AUTOSAR XML (schema 4-2-2)
package /STELLANTIS/EPT/ASWCs
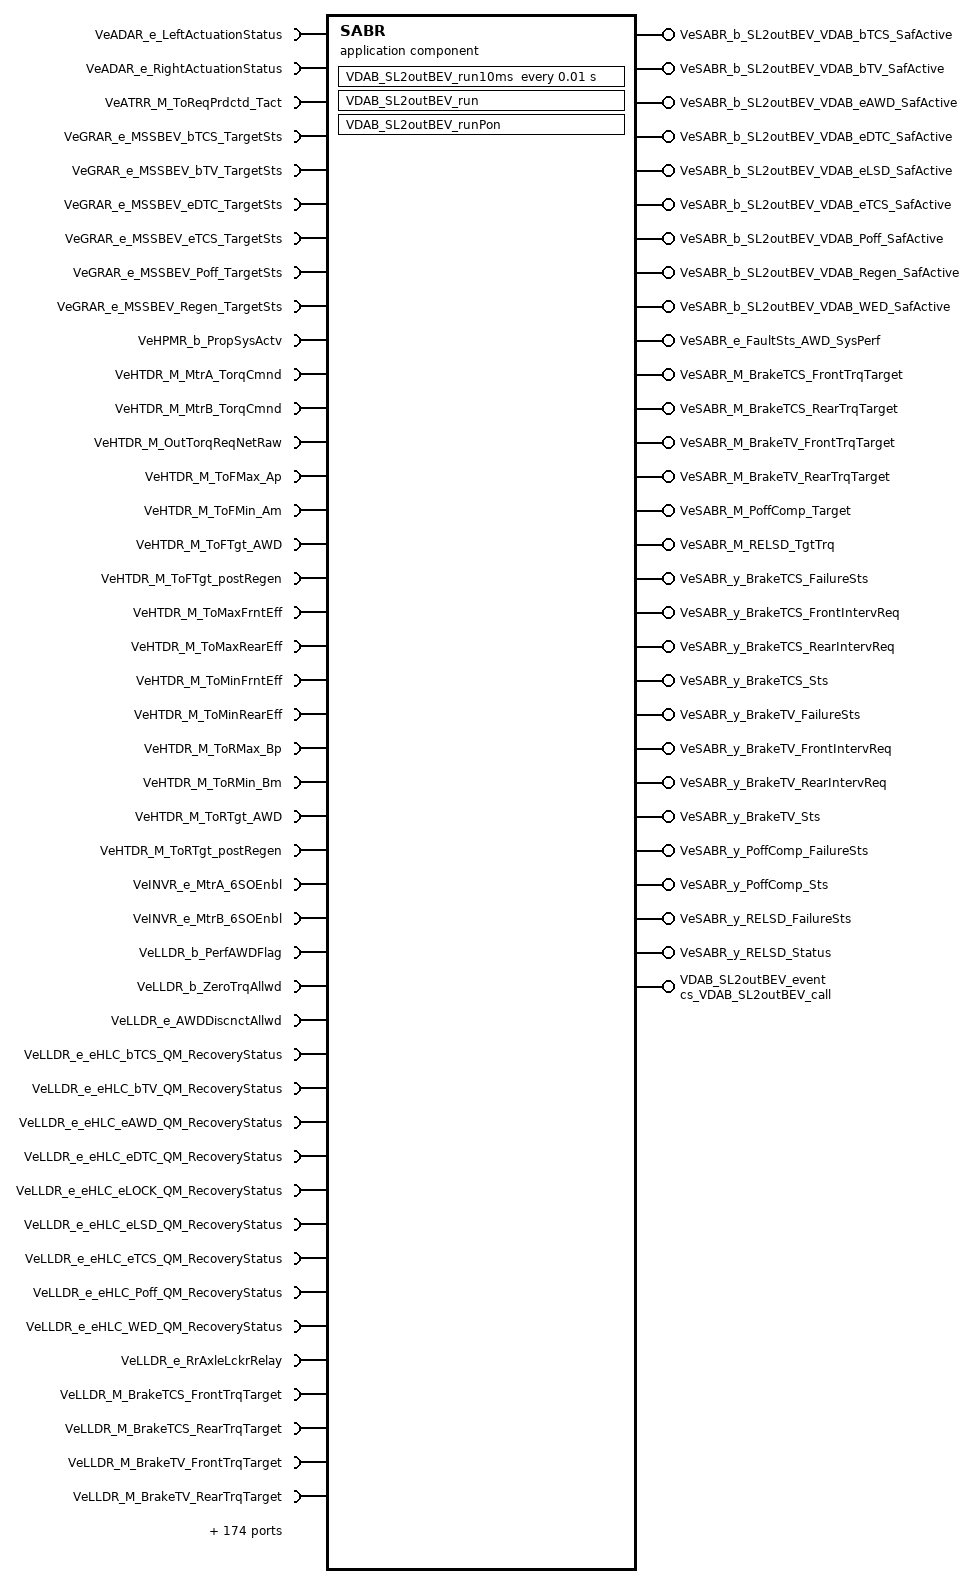
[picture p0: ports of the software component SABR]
  application sw component type SABR
    218 x require port:
      VeADAR_e_LeftActuationStatus: nonqueued-receiver-com-spec{data-element=Value, init-value=CeADAR_e_SS_Indeterminate}, required-interface=VeADAR_e_LeftActuationStatus
      VeADAR_e_RightActuationStatus: nonqueued-receiver-com-spec{data-element=Value, init-value=CeADAR_e_SS_Indeterminate}, required-interface=VeADAR_e_RightActuationStatus
      VeATRR_M_ToReqPrdctd_Tact: nonqueued-receiver-com-spec{data-element=Value, init-value=constant-reference=CONST_VeATRR_M_ToReqPrdctd_Tact_Init}, required-interface=VeATRR_M_ToReqPrdctd_Tact
      VeGRAR_e_MSSBEV_bTCS_TargetSts: nonqueued-receiver-com-spec{data-element=Value, init-value=CeGRAR_e_TargetSts_Disable}, required-interface=VeGRAR_e_MSSBEV_bTCS_TargetSts
      VeGRAR_e_MSSBEV_bTV_TargetSts: nonqueued-receiver-com-spec{data-element=Value, init-value=CeGRAR_e_TargetSts_Disable}, required-interface=VeGRAR_e_MSSBEV_bTV_TargetSts
      VeGRAR_e_MSSBEV_eDTC_TargetSts: nonqueued-receiver-com-spec{data-element=Value, init-value=CeGRAR_e_TargetSts_Disable}, required-interface=VeGRAR_e_MSSBEV_eDTC_TargetSts
      VeGRAR_e_MSSBEV_eTCS_TargetSts: nonqueued-receiver-com-spec{data-element=Value, init-value=CeGRAR_e_TargetSts_Disable}, required-interface=VeGRAR_e_MSSBEV_eTCS_TargetSts
      VeGRAR_e_MSSBEV_Poff_TargetSts: nonqueued-receiver-com-spec{data-element=Value, init-value=CeGRAR_e_TargetSts_Disable}, required-interface=VeGRAR_e_MSSBEV_Poff_TargetSts
      VeGRAR_e_MSSBEV_Regen_TargetSts: nonqueued-receiver-com-spec{data-element=Value, init-value=CeGRAR_e_TargetSts_Disable}, required-interface=VeGRAR_e_MSSBEV_Regen_TargetSts
      VeHPMR_b_PropSysActv: nonqueued-receiver-com-spec{data-element=Value, init-value=constant-reference=CONST_VeHPMR_b_PropSysActv_Init}, required-interface=VeHPMR_b_PropSysActv
      VeHTDR_M_MtrA_TorqCmnd: nonqueued-receiver-com-spec{data-element=Value, init-value=constant-reference=CONST_VeHTDR_M_MtrA_TorqCmnd_Init}, required-interface=VeHTDR_M_MtrA_TorqCmnd
      VeHTDR_M_MtrB_TorqCmnd: nonqueued-receiver-com-spec{data-element=Value, init-value=constant-reference=CONST_VeHTDR_M_MtrB_TorqCmnd_Init}, required-interface=VeHTDR_M_MtrB_TorqCmnd
      VeHTDR_M_OutTorqReqNetRaw: nonqueued-receiver-com-spec{data-element=Value, init-value=constant-reference=CONST_VeHTDR_M_OutTorqReqNetRaw_Init}, required-interface=VeHTDR_M_OutTorqReqNetRaw
      VeHTDR_M_ToFMax_Ap: nonqueued-receiver-com-spec{data-element=Value, init-value=constant-reference=CONST_VeHTDR_M_ToFMax_Ap_Init}, required-interface=VeHTDR_M_ToFMax_Ap
      VeHTDR_M_ToFMin_Am: nonqueued-receiver-com-spec{data-element=Value, init-value=constant-reference=CONST_VeHTDR_M_ToFMin_Am_Init}, required-interface=VeHTDR_M_ToFMin_Am
      VeHTDR_M_ToFTgt_AWD: nonqueued-receiver-com-spec{data-element=Value, init-value=constant-reference=CONST_VeHTDR_M_ToFTgt_AWD_Init}, required-interface=VeHTDR_M_ToFTgt_AWD
      VeHTDR_M_ToFTgt_postRegen: nonqueued-receiver-com-spec{data-element=Value, init-value=constant-reference=CONST_VeHTDR_M_ToFTgt_postRegen_Init}, required-interface=VeHTDR_M_ToFTgt_postRegen
      VeHTDR_M_ToMaxFrntEff: nonqueued-receiver-com-spec{data-element=Value, init-value=constant-reference=CONST_VeHTDR_M_ToMaxFrntEff_Init}, required-interface=VeHTDR_M_ToMaxFrntEff
      VeHTDR_M_ToMaxRearEff: nonqueued-receiver-com-spec{data-element=Value, init-value=constant-reference=CONST_VeHTDR_M_ToMaxRearEff_Init}, required-interface=VeHTDR_M_ToMaxRearEff
      VeHTDR_M_ToMinFrntEff: nonqueued-receiver-com-spec{data-element=Value, init-value=constant-reference=CONST_VeHTDR_M_ToMinFrntEff_Init}, required-interface=VeHTDR_M_ToMinFrntEff
      VeHTDR_M_ToMinRearEff: nonqueued-receiver-com-spec{data-element=Value, init-value=constant-reference=CONST_VeHTDR_M_ToMinRearEff_Init}, required-interface=VeHTDR_M_ToMinRearEff
      VeHTDR_M_ToRMax_Bp: nonqueued-receiver-com-spec{data-element=Value, init-value=constant-reference=CONST_VeHTDR_M_ToRMax_Bp_Init}, required-interface=VeHTDR_M_ToRMax_Bp
      VeHTDR_M_ToRMin_Bm: nonqueued-receiver-com-spec{data-element=Value, init-value=constant-reference=CONST_VeHTDR_M_ToRMin_Bm_Init}, required-interface=VeHTDR_M_ToRMin_Bm
      VeHTDR_M_ToRTgt_AWD: nonqueued-receiver-com-spec{data-element=Value, init-value=constant-reference=CONST_VeHTDR_M_ToRTgt_AWD_Init}, required-interface=VeHTDR_M_ToRTgt_AWD
      VeHTDR_M_ToRTgt_postRegen: nonqueued-receiver-com-spec{data-element=Value, init-value=constant-reference=CONST_VeHTDR_M_ToRTgt_postRegen_Init}, required-interface=VeHTDR_M_ToRTgt_postRegen
      VeINVR_e_MtrA_6SOEnbl: nonqueued-receiver-com-spec{data-element=Value, init-value=CeINVR_e_ThreePS}, required-interface=VeINVR_e_MtrA_6SOEnbl
      VeINVR_e_MtrB_6SOEnbl: nonqueued-receiver-com-spec{data-element=Value, init-value=CeINVR_e_ThreePS}, required-interface=VeINVR_e_MtrB_6SOEnbl
      VeLLDR_b_PerfAWDFlag: nonqueued-receiver-com-spec{data-element=Value, init-value=constant-reference=CONST_VeLLDR_b_eAWD_IntvActv_b_Init}, required-interface=VeLLDR_b_PerfAWDFlag
      VeLLDR_b_ZeroTrqAllwd: nonqueued-receiver-com-spec{data-element=Value, init-value=constant-reference=CONST_VeLLDR_b_eTCS_6SOAllowed_b_Init}, required-interface=VeLLDR_b_ZeroTrqAllwd
      VeLLDR_e_AWDDiscnctAllwd: nonqueued-receiver-com-spec{data-element=Value, init-value=constant-reference=CONST_VeLLDR_e_eTCS_AWDDisconnectAllowed_Init}, required-interface=VeLLDR_e_AWDDiscnctAllwd
      VeLLDR_e_eHLC_bTCS_QM_RecoveryStatus: nonqueued-receiver-com-spec{data-element=Value, init-value=constant-reference=CONST_VeLLDR_y_bTCS_RecoveryStatus_Init}, required-interface=VeLLDR_e_eHLC_bTCS_QM_RecoveryStatus
      VeLLDR_e_eHLC_bTV_QM_RecoveryStatus: nonqueued-receiver-com-spec{data-element=Value, init-value=constant-reference=CONST_VeLLDR_y_bTV_RecoveryStatus_Init}, required-interface=VeLLDR_e_eHLC_bTV_QM_RecoveryStatus
      VeLLDR_e_eHLC_eAWD_QM_RecoveryStatus: nonqueued-receiver-com-spec{data-element=Value, init-value=constant-reference=CONST_VeLLDR_e_eHLC_eAWD_QM_RecoveryStatus}, required-interface=VeLLDR_e_eHLC_eAWD_QM_RecoveryStatus
      VeLLDR_e_eHLC_eDTC_QM_RecoveryStatus: nonqueued-receiver-com-spec{data-element=Value, init-value=constant-reference=CONST_VeLLDR_y_eDTC_RecoveryStatus_Init}, required-interface=VeLLDR_e_eHLC_eDTC_QM_RecoveryStatus
      VeLLDR_e_eHLC_eLOCK_QM_RecoveryStatus: nonqueued-receiver-com-spec{data-element=Value, init-value=constant-reference=CONST_VeLLDR_e_eHLC_eLOCK_QM_RecoveryStatus_Init}, required-interface=VeLLDR_e_eHLC_eLOCK_QM_RecoveryStatus
      VeLLDR_e_eHLC_eLSD_QM_RecoveryStatus: nonqueued-receiver-com-spec{data-element=Value, init-value=constant-reference=CONST_VeLLDR_e_eHLC_eLSD_QM_RecoveryStatus_Init}, required-interface=VeLLDR_e_eHLC_eLSD_QM_RecoveryStatus
      VeLLDR_e_eHLC_eTCS_QM_RecoveryStatus: nonqueued-receiver-com-spec{data-element=Value, init-value=constant-reference=CONST_VeLLDR_y_eTCS_RecoveryStatus_Init}, required-interface=VeLLDR_e_eHLC_eTCS_QM_RecoveryStatus
      VeLLDR_e_eHLC_Poff_QM_RecoveryStatus: nonqueued-receiver-com-spec{data-element=Value, init-value=constant-reference=CONST_VeLLDR_y_Poff_RecoveryStatus_Init}, required-interface=VeLLDR_e_eHLC_Poff_QM_RecoveryStatus
      VeLLDR_e_eHLC_WED_QM_RecoveryStatus: nonqueued-receiver-com-spec{data-element=Value, init-value=constant-reference=CONST_VeLLDR_e_eHLC_WED_QM_RecoveryStatus_Init}, required-interface=VeLLDR_e_eHLC_WED_QM_RecoveryStatus
      VeLLDR_e_RrAxleLckrRelay: nonqueued-receiver-com-spec{data-element=Value, init-value=constant-reference=CONST_VeLLDR_e_eHLC_eLock_RrAxleLckrRelay_Init}, required-interface=VeLLDR_e_RrAxleLckrRelay
      VeLLDR_M_BrakeTCS_FrontTrqTarget: nonqueued-receiver-com-spec{data-element=Value, init-value=constant-reference=CONST_VeLLDR_M_BrakeTCS_FrontTrqTarget_Init}, required-interface=VeLLDR_M_BrakeTCS_FrontTrqTarget
      VeLLDR_M_BrakeTCS_RearTrqTarget: nonqueued-receiver-com-spec{data-element=Value, init-value=constant-reference=CONST_VeLLDR_M_BrakeTCS_RearTrqTarget_Init}, required-interface=VeLLDR_M_BrakeTCS_RearTrqTarget
      VeLLDR_M_BrakeTV_FrontTrqTarget: nonqueued-receiver-com-spec{data-element=Value, init-value=constant-reference=CONST_VeLLDR_M_BrakeTV_FrontTrqTarget_Init}, required-interface=VeLLDR_M_BrakeTV_FrontTrqTarget
      VeLLDR_M_BrakeTV_RearTrqTarget: nonqueued-receiver-com-spec{data-element=Value, init-value=constant-reference=CONST_VeLLDR_M_BrakeTV_RearTrqTarget_Init}, required-interface=VeLLDR_M_BrakeTV_RearTrqTarget
      VeLLDR_M_eHLC_eLSD_RELSD_TgtTrq: nonqueued-receiver-com-spec{data-element=Value, init-value=constant-reference=CONST_VeLLDR_M_eHLC_eLSD_RELSD_TgtTrq_Init}, required-interface=VeLLDR_M_eHLC_eLSD_RELSD_TgtTrq
      VeLLDR_M_FrntAxlAdhMax: nonqueued-receiver-com-spec{data-element=Value, init-value=constant-reference=CONST_VeLLDR_M_eTCS_Adherence_TrqMaxF_Nm_Init}, required-interface=VeLLDR_M_FrntAxlAdhMax
      VeLLDR_M_FrntAxlAdhMin: nonqueued-receiver-com-spec{data-element=Value, init-value=constant-reference=CONST_VeLLDR_M_eTCS_Adherence_TrqMinF_Nm_Init}, required-interface=VeLLDR_M_FrntAxlAdhMin
      VeLLDR_M_FrntAxlEffMax: nonqueued-receiver-com-spec{data-element=Value, init-value=constant-reference=CONST_VeLLDR_M_eTCS_Efficiency_TrqMaxF_Nm_Init}, required-interface=VeLLDR_M_FrntAxlEffMax
      VeLLDR_M_FrntAxlEffMin: nonqueued-receiver-com-spec{data-element=Value, init-value=constant-reference=CONST_VeLLDR_M_eTCS_Efficiency_TrqMinF_Nm_Init}, required-interface=VeLLDR_M_FrntAxlEffMin
      VeLLDR_M_FrntAxlMax_CL: nonqueued-receiver-com-spec{data-element=Value, init-value=constant-reference=CONST_VeLLDR_M_FrntAxlMax_CL_Init}, required-interface=VeLLDR_M_FrntAxlMax_CL
      VeLLDR_M_FrntAxlMax_OL: nonqueued-receiver-com-spec{data-element=Value, init-value=constant-reference=CONST_VeLLDR_M_eTCS_OL_TrqMaxF_Nm_Init}, required-interface=VeLLDR_M_FrntAxlMax_OL
      VeLLDR_M_FrntAxlMin_CL: nonqueued-receiver-com-spec{data-element=Value, init-value=constant-reference=CONST_VeLLDR_M_FrntAxlMin_CL_Init}, required-interface=VeLLDR_M_FrntAxlMin_CL
      VeLLDR_M_FrntAxlMin_OL: nonqueued-receiver-com-spec{data-element=Value, init-value=constant-reference=CONST_VeLLDR_M_eDTC_OL_TrqMinF_Nm_Init}, required-interface=VeLLDR_M_FrntAxlMin_OL
      VeLLDR_M_FrntAxlStrtgcMax_OL: nonqueued-receiver-com-spec{data-element=Value, init-value=constant-reference=CONST_VeLLDR_M_eTCS_OL_Strategic_TrqMaxF_Nm_Init}, required-interface=VeLLDR_M_FrntAxlStrtgcMax_OL
      VeLLDR_M_FrntAxlStrtgcMin_OL: nonqueued-receiver-com-spec{data-element=Value, init-value=constant-reference=CONST_VeLLDR_M_eTCS_OL_Strategic_TrqMinF_Nm_Init}, required-interface=VeLLDR_M_FrntAxlStrtgcMin_OL
      VeLLDR_M_FrntAxlTactFastMax_OL: nonqueued-receiver-com-spec{data-element=Value, init-value=constant-reference=CONST_VeLLDR_M_eTCS_OL_TactFast_TrqMaxF_Nm_Init}, required-interface=VeLLDR_M_FrntAxlTactFastMax_OL
      VeLLDR_M_FrntAxlTactFastMin_OL: nonqueued-receiver-com-spec{data-element=Value, init-value=constant-reference=CONST_VeLLDR_M_eTCS_OL_TactFast_TrqMinF_Nm_Init}, required-interface=VeLLDR_M_FrntAxlTactFastMin_OL
      VeLLDR_M_FrntAxlTactSlowMax_OL: nonqueued-receiver-com-spec{data-element=Value, init-value=constant-reference=CONST_VeLLDR_M_eTCS_OL_TactSlow_TrqMaxF_Nm_Init}, required-interface=VeLLDR_M_FrntAxlTactSlowMax_OL
      VeLLDR_M_FrntAxlTactSlowMin_OL: nonqueued-receiver-com-spec{data-element=Value, init-value=constant-reference=CONST_VeLLDR_M_eTCS_OL_TactSlow_TrqMinF_Nm_Init}, required-interface=VeLLDR_M_FrntAxlTactSlowMin_OL
      VeLLDR_M_PoffComp_Target: nonqueued-receiver-com-spec{data-element=Value, init-value=constant-reference=CONST_VeLLDR_M_PoffComp_Target_Init}, required-interface=VeLLDR_M_PoffComp_Target
      VeLLDR_M_RrAxlAdhMax: nonqueued-receiver-com-spec{data-element=Value, init-value=constant-reference=CONST_VeLLDR_M_eTCS_Adherence_TrqMaxR_Nm_Init}, required-interface=VeLLDR_M_RrAxlAdhMax
      VeLLDR_M_RrAxlAdhMin: nonqueued-receiver-com-spec{data-element=Value, init-value=constant-reference=CONST_VeLLDR_M_eTCS_Adherence_TrqMinR_Nm_Init}, required-interface=VeLLDR_M_RrAxlAdhMin
      VeLLDR_M_RrAxlEffMax: nonqueued-receiver-com-spec{data-element=Value, init-value=constant-reference=CONST_VeLLDR_M_eTCS_Efficiency_TrqMaxR_Nm_Init}, required-interface=VeLLDR_M_RrAxlEffMax
      VeLLDR_M_RrAxlEffMin: nonqueued-receiver-com-spec{data-element=Value, init-value=constant-reference=CONST_VeLLDR_M_eTCS_Efficiency_TrqMinR_Nm_Init}, required-interface=VeLLDR_M_RrAxlEffMin
      VeLLDR_M_RrAxlMax_CL: nonqueued-receiver-com-spec{data-element=Value, init-value=constant-reference=CONST_VeLLDR_M_RrAxlMax_CL_Init}, required-interface=VeLLDR_M_RrAxlMax_CL
      VeLLDR_M_RrAxlMax_OL: nonqueued-receiver-com-spec{data-element=Value, init-value=constant-reference=CONST_VeLLDR_M_eTCS_OL_TrqMaxR_Nm_Init}, required-interface=VeLLDR_M_RrAxlMax_OL
      VeLLDR_M_RrAxlMin_CL: nonqueued-receiver-com-spec{data-element=Value, init-value=constant-reference=CONST_VeLLDR_M_RrAxlMin_CL_Init}, required-interface=VeLLDR_M_RrAxlMin_CL
      VeLLDR_M_RrAxlMin_OL: nonqueued-receiver-com-spec{data-element=Value, init-value=constant-reference=CONST_VeLLDR_M_eDTC_OL_TrqMinR_Nm_Init}, required-interface=VeLLDR_M_RrAxlMin_OL
      VeLLDR_M_RrAxlStrtgcMax_OL: nonqueued-receiver-com-spec{data-element=Value, init-value=constant-reference=CONST_VeLLDR_M_eTCS_OL_Strategic_TrqMaxR_Nm_Init}, required-interface=VeLLDR_M_RrAxlStrtgcMax_OL
      VeLLDR_M_RrAxlStrtgcMin_OL: nonqueued-receiver-com-spec{data-element=Value, init-value=constant-reference=CONST_VeLLDR_M_eTCS_OL_Strategic_TrqMinR_Nm_Init}, required-interface=VeLLDR_M_RrAxlStrtgcMin_OL
      VeLLDR_M_RrAxlTactFastMax_OL: nonqueued-receiver-com-spec{data-element=Value, init-value=constant-reference=CONST_VeLLDR_M_eTCS_OL_TactFast_TrqMaxR_Nm_Init}, required-interface=VeLLDR_M_RrAxlTactFastMax_OL
      VeLLDR_M_RrAxlTactFastMin_OL: nonqueued-receiver-com-spec{data-element=Value, init-value=constant-reference=CONST_VeLLDR_M_eTCS_OL_TactFast_TrqMinR_Nm_Init}, required-interface=VeLLDR_M_RrAxlTactFastMin_OL
      VeLLDR_M_RrAxlTactSlowMax_OL: nonqueued-receiver-com-spec{data-element=Value, init-value=constant-reference=CONST_VeLLDR_M_eTCS_OL_TactSlow_TrqMaxR_Nm_Init}, required-interface=VeLLDR_M_RrAxlTactSlowMax_OL
      VeLLDR_M_RrAxlTactSlowMin_OL: nonqueued-receiver-com-spec{data-element=Value, init-value=constant-reference=CONST_VeLLDR_M_eTCS_OL_TactSlow_TrqMinR_Nm_Init}, required-interface=VeLLDR_M_RrAxlTactSlowMin_OL
      VeLLDR_r_eTCS_TireTolQual_FL: nonqueued-receiver-com-spec{data-element=Value, init-value=constant-reference=CONST_VeLLDR_r_eTCS_TireTolQual_FL_Init}, required-interface=VeLLDR_r_eTCS_TireTolQual_FL
      VeLLDR_r_eTCS_TireTolQual_FR: nonqueued-receiver-com-spec{data-element=Value, init-value=constant-reference=CONST_VeLLDR_r_eTCS_TireTolQual_FR_Init}, required-interface=VeLLDR_r_eTCS_TireTolQual_FR
      VeLLDR_r_eTCS_TireTolQual_RL: nonqueued-receiver-com-spec{data-element=Value, init-value=constant-reference=CONST_VeLLDR_r_eTCS_TireTolQual_RL_Init}, required-interface=VeLLDR_r_eTCS_TireTolQual_RL
      VeLLDR_r_eTCS_TireTolQual_RR: nonqueued-receiver-com-spec{data-element=Value, init-value=constant-reference=CONST_VeLLDR_r_eTCS_TireTolQual_RR_Init}, required-interface=VeLLDR_r_eTCS_TireTolQual_RR
      VeLLDR_r_eTCS_TireTolRatio_FL: nonqueued-receiver-com-spec{data-element=Value, init-value=constant-reference=CONST_VeLLDR_r_eTCS_TireTolRatio_FL_Init}, required-interface=VeLLDR_r_eTCS_TireTolRatio_FL
      VeLLDR_r_eTCS_TireTolRatio_FR: nonqueued-receiver-com-spec{data-element=Value, init-value=constant-reference=CONST_VeLLDR_r_eTCS_TireTolRatio_FR_Init}, required-interface=VeLLDR_r_eTCS_TireTolRatio_FR
      VeLLDR_r_eTCS_TireTolRatio_RL: nonqueued-receiver-com-spec{data-element=Value, init-value=constant-reference=CONST_VeLLDR_r_eTCS_TireTolRatio_RL_Init}, required-interface=VeLLDR_r_eTCS_TireTolRatio_RL
      VeLLDR_r_eTCS_TireTolRatio_RR: nonqueued-receiver-com-spec{data-element=Value, init-value=constant-reference=CONST_VeLLDR_r_eTCS_TireTolRatio_RR_Init}, required-interface=VeLLDR_r_eTCS_TireTolRatio_RR
      VeLLDR_r_RipAWD: nonqueued-receiver-com-spec{data-element=Value, init-value=constant-reference=CONST_VeLLDR_K_eAWD_SplitFactor_Plus_Init}, required-interface=VeLLDR_r_RipAWD
      VeLLDR_r_RipRegen: nonqueued-receiver-com-spec{data-element=Value, init-value=constant-reference=CONST_VeLLDR_K_eAWD_SplitFactor_Minus_Init}, required-interface=VeLLDR_r_RipRegen
      VeLLDR_v_eTCS_VxEst_kmph: nonqueued-receiver-com-spec{data-element=Value, init-value=constant-reference=CONST_VeLLDR_v_eTCS_VxEst_kmph_Init}, required-interface=VeLLDR_v_eTCS_VxEst_kmph
      VeLLDR_y_BrakeTCS_FrontIntervReq: nonqueued-receiver-com-spec{data-element=Value, init-value=constant-reference=CONST_VeLLDR_y_BrakeTCS_FrontIntervReq_Init}, required-interface=VeLLDR_y_BrakeTCS_FrontIntervReq
      VeLLDR_y_BrakeTCS_RearIntervReq: nonqueued-receiver-com-spec{data-element=Value, init-value=constant-reference=CONST_VeLLDR_y_BrakeTCS_RearIntervReq_Init}, required-interface=VeLLDR_y_BrakeTCS_RearIntervReq
      VeLLDR_y_BrakeTV_FrontIntervReq: nonqueued-receiver-com-spec{data-element=Value, init-value=constant-reference=CONST_VeLLDR_y_BrakeTV_FrontIntervReq_Init}, required-interface=VeLLDR_y_BrakeTV_FrontIntervReq
      VeLLDR_y_BrakeTV_RearIntervReq: nonqueued-receiver-com-spec{data-element=Value, init-value=constant-reference=CONST_VeLLDR_y_BrakeTV_RearIntervReq_Init}, required-interface=VeLLDR_y_BrakeTV_RearIntervReq
      VePSMR_b_Lv2AccelPdlPosFlt: nonqueued-receiver-com-spec{data-element=Value, init-value=constant-reference=CONST_VePSMR_b_Lv2AccelPdlPosFlt_Init}, required-interface=VePSMR_b_Lv2AccelPdlPosFlt
      VePSMR_Pct_Lv2AccelPdlPos: nonqueued-receiver-com-spec{data-element=Value, init-value=constant-reference=CONST_VePSMR_Pct_Lv2AccelPdlPos_Init}, required-interface=VePSMR_Pct_Lv2AccelPdlPos
      VeRGNR_M_RegenBrkOutTorqCap_Frnt: nonqueued-receiver-com-spec{data-element=Value, init-value=constant-reference=CONST_VeRGNR_M_RegenBrkOutTorqCap_Frnt_Init}, required-interface=VeRGNR_M_RegenBrkOutTorqCap_Frnt
      VeRGNR_M_RegenBrkOutTorqCap_Rear: nonqueued-receiver-com-spec{data-element=Value, init-value=constant-reference=CONST_VeRGNR_M_RegenBrkOutTorqCap_Rear_Init}, required-interface=VeRGNR_M_RegenBrkOutTorqCap_Rear
      VeRGNR_r_RIPEfficiency: nonqueued-receiver-com-spec{data-element=Value, init-value=constant-reference=CONST_VeRGNR_r_RIPEfficiency_Init}, required-interface=VeRGNR_r_RIPEfficiency
      VeSCMR_a_Lv2LatAcceleration: nonqueued-receiver-com-spec{data-element=Value, init-value=constant-reference=CONST_VeSCMR_a_Lv2LatAcceleration_Init}, required-interface=VeSCMR_a_Lv2LatAcceleration
      VeSCMR_a_Lv2LongAcceleration: nonqueued-receiver-com-spec{data-element=Value, init-value=constant-reference=CONST_VeSCMR_a_Lv2LongAcceleration_Init}, required-interface=VeSCMR_a_Lv2LongAcceleration
      VeSCMR_b_Lv2ABSActive: nonqueued-receiver-com-spec{data-element=Value, init-value=constant-reference=CONST_VeSCMR_b_Lv2ABSActive_Init}, required-interface=VeSCMR_b_Lv2ABSActive
      VeSCMR_b_Lv2ABSActive_FA: nonqueued-receiver-com-spec{data-element=Value, init-value=constant-reference=CONST_VeSCMR_b_Lv2ABSActive_FA_Init}, required-interface=VeSCMR_b_Lv2ABSActive_FA
      VeSCMR_b_Lv2ABSFailSts: nonqueued-receiver-com-spec{data-element=Value, init-value=constant-reference=CONST_VeSCMR_b_Lv2ABSFailSts_Init}, required-interface=VeSCMR_b_Lv2ABSFailSts
      VeSCMR_b_Lv2ABSFailSts_FA: nonqueued-receiver-com-spec{data-element=Value, init-value=constant-reference=CONST_VeSCMR_b_Lv2ABSFailSts_FA_Init}, required-interface=VeSCMR_b_Lv2ABSFailSts_FA
      VeSCMR_b_Lv2ACC_SystemSts_FA: nonqueued-receiver-com-spec{data-element=Value, init-value=constant-reference=CONST_VeSCMR_b_Lv2ACC_SystemSts_FA_Init}, required-interface=VeSCMR_b_Lv2ACC_SystemSts_FA
      VeSCMR_b_Lv2Brk_Stat_FA: nonqueued-receiver-com-spec{data-element=Value, init-value=constant-reference=CONST_VeSCMR_b_Lv2Brk_Stat_FA_Init}, required-interface=VeSCMR_b_Lv2Brk_Stat_FA
      VeSCMR_b_Lv2BrkBoostPressure_FA: nonqueued-receiver-com-spec{data-element=Value, init-value=constant-reference=CONST_VeSCMR_b_Lv2BrkBoostPressure_FA_Init}, required-interface=VeSCMR_b_Lv2BrkBoostPressure_FA
      VeSCMR_b_Lv2BrkPdl_Flt: nonqueued-receiver-com-spec{data-element=Value, init-value=constant-reference=CONST_VeSCMR_b_Lv2BrkPdl_Flt_Init}, required-interface=VeSCMR_b_Lv2BrkPdl_Flt
      VeSCMR_b_Lv2BrkPdl_Flt_FA: nonqueued-receiver-com-spec{data-element=Value, init-value=constant-reference=CONST_VeSCMR_b_Lv2BrkPdl_Flt_FA_Init}, required-interface=VeSCMR_b_Lv2BrkPdl_Flt_FA
      VeSCMR_b_Lv2BrkPdlStat_FA: nonqueued-receiver-com-spec{data-element=Value, init-value=constant-reference=CONST_VeSCMR_b_Lv2BrkPdlStat_FA_Init}, required-interface=VeSCMR_b_Lv2BrkPdlStat_FA
      VeSCMR_b_Lv2BrkTravelSts_FA: nonqueued-receiver-com-spec{data-element=Value, init-value=constant-reference=CONST_VeSCMR_b_Lv2BrkTravelSts_FA_Init}, required-interface=VeSCMR_b_Lv2BrkTravelSts_FA
      VeSCMR_b_Lv2BrkTrq_FA: nonqueued-receiver-com-spec{data-element=Value, init-value=constant-reference=CONST_VeSCMR_b_Lv2BrkTrq_FA_Init}, required-interface=VeSCMR_b_Lv2BrkTrq_FA
      VeSCMR_b_Lv2BrkTrqDriver_FA: nonqueued-receiver-com-spec{data-element=Value, init-value=constant-reference=CONST_VeSCMR_b_Lv2BrkTrqDriver_FA_Init}, required-interface=VeSCMR_b_Lv2BrkTrqDriver_FA
      VeSCMR_b_Lv2EPB_HoldSts_FA: nonqueued-receiver-com-spec{data-element=Value, init-value=constant-reference=CONST_VeSCMR_b_Lv2EPB_HoldSts_FA_Init}, required-interface=VeSCMR_b_Lv2EPB_HoldSts_FA
      VeSCMR_b_Lv2ESC_Active: nonqueued-receiver-com-spec{data-element=Value, init-value=constant-reference=CONST_VeSCMR_b_Lv2ESC_Active_Init}, required-interface=VeSCMR_b_Lv2ESC_Active
      VeSCMR_b_Lv2ESC_Active_FA: nonqueued-receiver-com-spec{data-element=Value, init-value=constant-reference=CONST_VeSCMR_b_Lv2ESC_Active_FA_Init}, required-interface=VeSCMR_b_Lv2ESC_Active_FA
      VeSCMR_b_Lv2ESC_FailSts: nonqueued-receiver-com-spec{data-element=Value, init-value=constant-reference=CONST_VeSCMR_b_Lv2ESC_FailSts_Init}, required-interface=VeSCMR_b_Lv2ESC_FailSts
      VeSCMR_b_Lv2ESC_FailSts_FA: nonqueued-receiver-com-spec{data-element=Value, init-value=constant-reference=CONST_VeSCMR_b_Lv2ESC_FailSts_FA_Init}, required-interface=VeSCMR_b_Lv2ESC_FailSts_FA
      VeSCMR_b_Lv2Function2Sts: nonqueued-receiver-com-spec{data-element=Value, init-value=constant-reference=CONST_VeSCMR_b_Lv2Function2Sts_Init}, required-interface=VeSCMR_b_Lv2Function2Sts
      VeSCMR_b_Lv2Function2Sts_FA: nonqueued-receiver-com-spec{data-element=Value, init-value=constant-reference=CONST_VeSCMR_b_Lv2Function2Sts_FA_Init}, required-interface=VeSCMR_b_Lv2Function2Sts_FA
      VeSCMR_b_Lv2GearShiftType_FA: nonqueued-receiver-com-spec{data-element=Value, init-value=constant-reference=CONST_VeSCMR_b_Lv2GearShiftType_FA_Init}, required-interface=VeSCMR_b_Lv2GearShiftType_FA
      VeSCMR_b_Lv2KeySts_FA: nonqueued-receiver-com-spec{data-element=Value, init-value=constant-reference=CONST_VeSCMR_b_Lv2KeySts_FA_Init}, required-interface=VeSCMR_b_Lv2KeySts_FA
      VeSCMR_b_Lv2LatAcceleration_FA: nonqueued-receiver-com-spec{data-element=Value, init-value=constant-reference=CONST_VeSCMR_b_Lv2LatAcceleration_FA_Init}, required-interface=VeSCMR_b_Lv2LatAcceleration_FA
      VeSCMR_b_Lv2LatAccelerationFailSts: nonqueued-receiver-com-spec{data-element=Value, init-value=constant-reference=CONST_VeSCMR_b_Lv2LatAccelerationFailSts_Init}, required-interface=VeSCMR_b_Lv2LatAccelerationFailSts
      VeSCMR_b_Lv2LatAccelerationFailSts_FA: nonqueued-receiver-com-spec{data-element=Value, init-value=constant-reference=CONST_VeSCMR_b_Lv2LatAccelerationFailSts_FA_Init}, required-interface=VeSCMR_b_Lv2LatAccelerationFailSts_FA
      VeSCMR_b_Lv2LongAcceleration_FA: nonqueued-receiver-com-spec{data-element=Value, init-value=constant-reference=CONST_VeSCMR_b_Lv2LongAcceleration_FA_Init}, required-interface=VeSCMR_b_Lv2LongAcceleration_FA
      VeSCMR_b_Lv2LongAccelerationFailSts: nonqueued-receiver-com-spec{data-element=Value, init-value=constant-reference=CONST_VeSCMR_b_Lv2LongAccelerationFailSts_Init}, required-interface=VeSCMR_b_Lv2LongAccelerationFailSts
      VeSCMR_b_Lv2LongAccelerationFailSts_FA: nonqueued-receiver-com-spec{data-element=Value, init-value=constant-reference=CONST_VeSCMR_b_Lv2LongAccelerationFailSts_FA_Init}, required-interface=VeSCMR_b_Lv2LongAccelerationFailSts_FA
      VeSCMR_b_Lv2LwsAngle_FA: nonqueued-receiver-com-spec{data-element=Value, init-value=constant-reference=CONST_VeSCMR_b_Lv2LwsAngle_FA_Init}, required-interface=VeSCMR_b_Lv2LwsAngle_FA
      VeSCMR_b_Lv2MRGB_Current_Gr_FA: nonqueued-receiver-com-spec{data-element=Value, init-value=constant-reference=CONST_VeSCMR_b_Lv2MRGB_Current_Gr_FA_Init}, required-interface=VeSCMR_b_Lv2MRGB_Current_Gr_FA
      VeSCMR_b_Lv2MRGB_Target_Gr_FA: nonqueued-receiver-com-spec{data-element=Value, init-value=constant-reference=CONST_VeSCMR_b_Lv2MRGB_Target_Gr_FA_Init}, required-interface=VeSCMR_b_Lv2MRGB_Target_Gr_FA
      VeSCMR_b_Lv2MtrA_MaxTrq_FA: nonqueued-receiver-com-spec{data-element=Value, init-value=constant-reference=CONST_VeSCMR_b_Lv2MtrA_MaxTrq_FA_Init}, required-interface=VeSCMR_b_Lv2MtrA_MaxTrq_FA
      VeSCMR_b_Lv2MtrA_MinTrq_FA: nonqueued-receiver-com-spec{data-element=Value, init-value=constant-reference=CONST_VeSCMR_b_Lv2MtrA_MinTrq_FA_Init}, required-interface=VeSCMR_b_Lv2MtrA_MinTrq_FA
      VeSCMR_b_Lv2MtrA_Spd_Vld: nonqueued-receiver-com-spec{data-element=Value, init-value=constant-reference=CONST_VeSCMR_b_Lv2MtrA_Spd_Vld_Init}, required-interface=VeSCMR_b_Lv2MtrA_Spd_Vld
      VeSCMR_b_Lv2MtrA_TrqAchieved_Vld: nonqueued-receiver-com-spec{data-element=Value, init-value=constant-reference=CONST_VeSCMR_b_Lv2MtrA_TrqAchieved_Vld_Init}, required-interface=VeSCMR_b_Lv2MtrA_TrqAchieved_Vld
      VeSCMR_b_Lv2MtrA_TrqAchieved_NoAEMD_FA: nonqueued-receiver-com-spec{data-element=Value, init-value=constant-reference=CONST_VeSCMR_b_Lv2MtrA_TrqAchieved_NoAEMD_FA_Init}, required-interface=VeSCMR_b_Lv2MtrA_TrqAchieved_NoAEMD_FA
      VeSCMR_b_Lv2MtrB_MaxTrq_FA: nonqueued-receiver-com-spec{data-element=Value, init-value=constant-reference=CONST_VeSCMR_b_Lv2MtrB_MaxTrq_FA_Init}, required-interface=VeSCMR_b_Lv2MtrB_MaxTrq_FA
      VeSCMR_b_Lv2MtrB_MinTrq_FA: nonqueued-receiver-com-spec{data-element=Value, init-value=constant-reference=CONST_VeSCMR_b_Lv2MtrB_MinTrq_FA_Init}, required-interface=VeSCMR_b_Lv2MtrB_MinTrq_FA
      VeSCMR_b_Lv2MtrB_Spd_Vld: nonqueued-receiver-com-spec{data-element=Value, init-value=constant-reference=CONST_VeSCMR_b_Lv2MtrB_Spd_Vld_Init}, required-interface=VeSCMR_b_Lv2MtrB_Spd_Vld
      VeSCMR_b_Lv2MtrB_TrqAchieved_Vld: nonqueued-receiver-com-spec{data-element=Value, init-value=constant-reference=CONST_VeSCMR_b_Lv2MtrB_TrqAchieved_Vld_Init}, required-interface=VeSCMR_b_Lv2MtrB_TrqAchieved_Vld
      VeSCMR_b_Lv2MtrB_TrqAchieved_NoAEMD_FA: nonqueued-receiver-com-spec{data-element=Value, init-value=constant-reference=CONST_VeSCMR_b_Lv2MtrB_TrqAchieved_NoAEMD_FA_Init}, required-interface=VeSCMR_b_Lv2MtrB_TrqAchieved_NoAEMD_FA
      VeSCMR_b_Lv2OperationalModeSts_FA: nonqueued-receiver-com-spec{data-element=Value, init-value=constant-reference=CONST_VeSCMR_b_Lv2OperationalModeSts_FA_Init}, required-interface=VeSCMR_b_Lv2OperationalModeSts_FA
      VeSCMR_b_Lv2RollsModeAct: nonqueued-receiver-com-spec{data-element=Value, init-value=constant-reference=CONST_VeSCMR_b_Lv2RollsModeAct_Init}, required-interface=VeSCMR_b_Lv2RollsModeAct
      VeSCMR_b_Lv2RollsModeAct_FA: nonqueued-receiver-com-spec{data-element=Value, init-value=constant-reference=CONST_VeSCMR_b_Lv2RollsModeAct_FA_Init}, required-interface=VeSCMR_b_Lv2RollsModeAct_FA
      VeSCMR_b_Lv2RrLkTrq_FA: nonqueued-receiver-com-spec{data-element=Value, init-value=constant-reference=CONST_VeSR1B_y_RrLkTrq_SigSts_Init}, required-interface=VeSCMR_b_Lv2RrLkTrq_FA
      VeSCMR_b_Lv2RrSysStat_FA: nonqueued-receiver-com-spec{data-element=Value, init-value=constant-reference=CONST_VeSCMR_b_Lv2RrSysStat_FA_Init}, required-interface=VeSCMR_b_Lv2RrSysStat_FA
      VeSCMR_b_Lv2RrTemp_Avl_FA: nonqueued-receiver-com-spec{data-element=Value, init-value=constant-reference=CONST_VeSCMR_b_Lv2RrTemp_Avl_FA_Init}, required-interface=VeSCMR_b_Lv2RrTemp_Avl_FA
      VeSCMR_b_Lv2TransTrqRatio_FA: nonqueued-receiver-com-spec{data-element=Value, init-value=constant-reference=CONST_VeSCMR_b_Lv2TransTrqRatio_FA_Init}, required-interface=VeSCMR_b_Lv2TransTrqRatio_FA
      VeSCMR_b_Lv2WhlDirFL_Stat_FA: nonqueued-receiver-com-spec{data-element=Value, init-value=constant-reference=CONST_VeSCMR_b_Lv2WhlDirFL_Stat_FA_Init}, required-interface=VeSCMR_b_Lv2WhlDirFL_Stat_FA
      VeSCMR_b_Lv2WhlDirFR_Stat_FA: nonqueued-receiver-com-spec{data-element=Value, init-value=constant-reference=CONST_VeSCMR_b_Lv2WhlDirFR_Stat_FA_Init}, required-interface=VeSCMR_b_Lv2WhlDirFR_Stat_FA
      VeSCMR_b_Lv2WhlDirRL_Stat_FA: nonqueued-receiver-com-spec{data-element=Value, init-value=constant-reference=CONST_VeSCMR_b_Lv2WhlDirRL_Stat_FA_Init}, required-interface=VeSCMR_b_Lv2WhlDirRL_Stat_FA
      VeSCMR_b_Lv2WhlDirRR_Stat_FA: nonqueued-receiver-com-spec{data-element=Value, init-value=constant-reference=CONST_VeSCMR_b_Lv2WhlDirRR_Stat_FA_Init}, required-interface=VeSCMR_b_Lv2WhlDirRR_Stat_FA
      VeSCMR_b_Lv2WhlFL_Spd_FA: nonqueued-receiver-com-spec{data-element=Value, init-value=constant-reference=CONST_VeSCMR_b_Lv2WhlFL_Spd_FA_Init}, required-interface=VeSCMR_b_Lv2WhlFL_Spd_FA
      VeSCMR_b_Lv2WhlFR_Spd_FA: nonqueued-receiver-com-spec{data-element=Value, init-value=constant-reference=CONST_VeSCMR_b_Lv2WhlFR_Spd_FA_Init}, required-interface=VeSCMR_b_Lv2WhlFR_Spd_FA
      VeSCMR_b_Lv2WhlRL_Spd_FA: nonqueued-receiver-com-spec{data-element=Value, init-value=constant-reference=CONST_VeSCMR_b_Lv2WhlRL_Spd_FA_Init}, required-interface=VeSCMR_b_Lv2WhlRL_Spd_FA
      VeSCMR_b_Lv2WhlRR_Spd_FA: nonqueued-receiver-com-spec{data-element=Value, init-value=constant-reference=CONST_VeSCMR_b_Lv2WhlRR_Spd_FA_Init}, required-interface=VeSCMR_b_Lv2WhlRR_Spd_FA
      VeSCMR_b_Lv2WhlSensFailFL: nonqueued-receiver-com-spec{data-element=Value, init-value=constant-reference=CONST_VeSCMR_b_Lv2WhlSensFailFL_Init}, required-interface=VeSCMR_b_Lv2WhlSensFailFL
      VeSCMR_b_Lv2WhlSensFailFL_FA: nonqueued-receiver-com-spec{data-element=Value, init-value=constant-reference=CONST_VeSCMR_b_Lv2WhlSensFailFL_FA_Init}, required-interface=VeSCMR_b_Lv2WhlSensFailFL_FA
      VeSCMR_b_Lv2WhlSensFailFR: nonqueued-receiver-com-spec{data-element=Value, init-value=constant-reference=CONST_VeSCMR_b_Lv2WhlSensFailFR_Init}, required-interface=VeSCMR_b_Lv2WhlSensFailFR
      VeSCMR_b_Lv2WhlSensFailFR_FA: nonqueued-receiver-com-spec{data-element=Value, init-value=constant-reference=CONST_VeSCMR_b_Lv2WhlSensFailFR_FA_Init}, required-interface=VeSCMR_b_Lv2WhlSensFailFR_FA
      VeSCMR_b_Lv2WhlSensFailRL: nonqueued-receiver-com-spec{data-element=Value, init-value=constant-reference=CONST_VeSCMR_b_Lv2WhlSensFailRL_Init}, required-interface=VeSCMR_b_Lv2WhlSensFailRL
      VeSCMR_b_Lv2WhlSensFailRL_FA: nonqueued-receiver-com-spec{data-element=Value, init-value=constant-reference=CONST_VeSCMR_b_Lv2WhlSensFailRL_FA_Init}, required-interface=VeSCMR_b_Lv2WhlSensFailRL_FA
      VeSCMR_b_Lv2WhlSensFailRR: nonqueued-receiver-com-spec{data-element=Value, init-value=constant-reference=CONST_VeSCMR_b_Lv2WhlSensFailRR_Init}, required-interface=VeSCMR_b_Lv2WhlSensFailRR
      VeSCMR_b_Lv2WhlSensFailRR_FA: nonqueued-receiver-com-spec{data-element=Value, init-value=constant-reference=CONST_VeSCMR_b_Lv2WhlSensFailRR_FA_Init}, required-interface=VeSCMR_b_Lv2WhlSensFailRR_FA
      VeSCMR_b_Lv2YawRate_FA: nonqueued-receiver-com-spec{data-element=Value, init-value=constant-reference=CONST_VeSCMR_b_Lv2YawRate_FA_Init}, required-interface=VeSCMR_b_Lv2YawRate_FA
      VeSCMR_b_Lv2YawRateFailSts: nonqueued-receiver-com-spec{data-element=Value, init-value=constant-reference=CONST_VeSCMR_b_Lv2YawRateFailSts_Init}, required-interface=VeSCMR_b_Lv2YawRateFailSts
      VeSCMR_b_Lv2YawRateFailSts_FA: nonqueued-receiver-com-spec{data-element=Value, init-value=constant-reference=CONST_VeSCMR_b_Lv2YawRateFailSts_FA_Init}, required-interface=VeSCMR_b_Lv2YawRateFailSts_FA
      VeSCMR_dphi_Lv2YawRate: nonqueued-receiver-com-spec{data-element=Value, init-value=constant-reference=CONST_VeSCMR_dphi_Lv2YawRate_Init}, required-interface=VeSCMR_dphi_Lv2YawRate
      VeSCMR_e_Lv2ACC_SystemSts: nonqueued-receiver-com-spec{data-element=Value, init-value=CeSTMR_e_Off_M182}, required-interface=VeSCMR_e_Lv2ACC_SystemSts
      VeSCMR_e_Lv2Brk_Stat: nonqueued-receiver-com-spec{data-element=Value, init-value=constant-reference=CONST_VeSCMR_e_Lv2Brk_Stat_Init}, required-interface=VeSCMR_e_Lv2Brk_Stat
      VeSCMR_e_Lv2BrkPdlStat: nonqueued-receiver-com-spec{data-element=Value, init-value=constant-reference=CONST_VeSCMR_e_Lv2BrkPdlStat_Init}, required-interface=VeSCMR_e_Lv2BrkPdlStat
      VeSCMR_e_Lv2EPB_HoldSts: nonqueued-receiver-com-spec{data-element=Value, init-value=CeSTMR_e_EPBHoldSts_REL}, required-interface=VeSCMR_e_Lv2EPB_HoldSts
      VeSCMR_e_Lv2KeySts: nonqueued-receiver-com-spec{data-element=Value, init-value=CeLTIR_e_IGN_LK}, required-interface=VeSCMR_e_Lv2KeySts
      VeSCMR_e_Lv2RrSysStat: nonqueued-receiver-com-spec{data-element=Value, init-value=constant-reference=CONST_VeSCMR_e_Lv2RrSysStat_Init}, required-interface=VeSCMR_e_Lv2RrSysStat
      VeSCMR_e_Lv2WhlDirFL_Stat: nonqueued-receiver-com-spec{data-element=Value, init-value=constant-reference=CONST_VeSCMR_e_Lv2WhlDirFL_Stat_Init}, required-interface=VeSCMR_e_Lv2WhlDirFL_Stat
      VeSCMR_e_Lv2WhlDirFR_Stat: nonqueued-receiver-com-spec{data-element=Value, init-value=constant-reference=CONST_VeSCMR_e_Lv2WhlDirFR_Stat_Init}, required-interface=VeSCMR_e_Lv2WhlDirFR_Stat
      VeSCMR_e_Lv2WhlDirRL_Stat: nonqueued-receiver-com-spec{data-element=Value, init-value=constant-reference=CONST_VeSCMR_e_Lv2WhlDirRL_Stat_Init}, required-interface=VeSCMR_e_Lv2WhlDirRL_Stat
      VeSCMR_e_Lv2WhlDirRR_Stat: nonqueued-receiver-com-spec{data-element=Value, init-value=constant-reference=CONST_VeSCMR_e_Lv2WhlDirRR_Stat_Init}, required-interface=VeSCMR_e_Lv2WhlDirRR_Stat
      VeSCMR_M_Lv2BrkTrq: nonqueued-receiver-com-spec{data-element=Value, init-value=constant-reference=CONST_VeSCMR_M_Lv2BrkTrq_Init}, required-interface=VeSCMR_M_Lv2BrkTrq
      VeSCMR_M_Lv2BrkTrqDriver: nonqueued-receiver-com-spec{data-element=Value, init-value=constant-reference=CONST_VeSCMR_M_Lv2BrkTrqDriver_Init}, required-interface=VeSCMR_M_Lv2BrkTrqDriver
      VeSCMR_M_Lv2MtrA_MaxTrq: nonqueued-receiver-com-spec{data-element=Value, init-value=constant-reference=CONST_VeSCMR_M_Lv2MtrA_MaxTrq_Init}, required-interface=VeSCMR_M_Lv2MtrA_MaxTrq
      VeSCMR_M_Lv2MtrA_MinTrq: nonqueued-receiver-com-spec{data-element=Value, init-value=constant-reference=CONST_VeSCMR_M_Lv2MtrA_MinTrq_Init}, required-interface=VeSCMR_M_Lv2MtrA_MinTrq
      VeSCMR_M_Lv2MtrA_TrqAchieved: nonqueued-receiver-com-spec{data-element=Value, init-value=constant-reference=CONST_VeSCMR_M_Lv2MtrA_TrqAchieved_Init}, required-interface=VeSCMR_M_Lv2MtrA_TrqAchieved
      VeSCMR_M_Lv2MtrA_TrqAchieved_NoAEMD: nonqueued-receiver-com-spec{data-element=Value, init-value=constant-reference=CONST_VeSCMR_M_Lv2MtrA_TrqAchieved_NoAEMD_Init}, required-interface=VeSCMR_M_Lv2MtrA_TrqAchieved_NoAEMD
      VeSCMR_M_Lv2MtrB_MaxTrq: nonqueued-receiver-com-spec{data-element=Value, init-value=constant-reference=CONST_VeSCMR_M_Lv2MtrB_MaxTrq_Init}, required-interface=VeSCMR_M_Lv2MtrB_MaxTrq
      VeSCMR_M_Lv2MtrB_MinTrq: nonqueued-receiver-com-spec{data-element=Value, init-value=constant-reference=CONST_VeSCMR_M_Lv2MtrB_MinTrq_Init}, required-interface=VeSCMR_M_Lv2MtrB_MinTrq
      VeSCMR_M_Lv2MtrB_TrqAchieved: nonqueued-receiver-com-spec{data-element=Value, init-value=constant-reference=CONST_VeSCMR_M_Lv2MtrB_TrqAchieved_Init}, required-interface=VeSCMR_M_Lv2MtrB_TrqAchieved
      VeSCMR_M_Lv2MtrB_TrqAchieved_NoAEMD: nonqueued-receiver-com-spec{data-element=Value, init-value=constant-reference=CONST_VeSCMR_M_Lv2MtrB_TrqAchieved_NoAEMD_Init}, required-interface=VeSCMR_M_Lv2MtrB_TrqAchieved_NoAEMD
      VeSCMR_M_Lv2RrLkTrq: nonqueued-receiver-com-spec{data-element=Value, init-value=constant-reference=CONST_VeSCMR_M_Lv2RrLkTrq_Init}, required-interface=VeSCMR_M_Lv2RrLkTrq
      VeSCMR_n_Lv2MtrA_Spd: nonqueued-receiver-com-spec{data-element=Value, init-value=constant-reference=CONST_VeSCMR_n_Lv2MtrA_Spd_Init}, required-interface=VeSCMR_n_Lv2MtrA_Spd
      VeSCMR_n_Lv2MtrB_Spd: nonqueued-receiver-com-spec{data-element=Value, init-value=constant-reference=CONST_VeSCMR_n_Lv2MtrB_Spd_Init}, required-interface=VeSCMR_n_Lv2MtrB_Spd
      VeSCMR_n_Lv2WhlFL_Spd: nonqueued-receiver-com-spec{data-element=Value, init-value=constant-reference=CONST_VeSCMR_n_Lv2WhlFL_Spd_Init}, required-interface=VeSCMR_n_Lv2WhlFL_Spd
      VeSCMR_n_Lv2WhlFR_Spd: nonqueued-receiver-com-spec{data-element=Value, init-value=constant-reference=CONST_VeSCMR_n_Lv2WhlFR_Spd_Init}, required-interface=VeSCMR_n_Lv2WhlFR_Spd
      VeSCMR_n_Lv2WhlRL_Spd: nonqueued-receiver-com-spec{data-element=Value, init-value=constant-reference=CONST_VeSCMR_n_Lv2WhlRL_Spd_Init}, required-interface=VeSCMR_n_Lv2WhlRL_Spd
      VeSCMR_n_Lv2WhlRR_Spd: nonqueued-receiver-com-spec{data-element=Value, init-value=constant-reference=CONST_VeSCMR_n_Lv2WhlRR_Spd_Init}, required-interface=VeSCMR_n_Lv2WhlRR_Spd
      VeSCMR_p_Lv2BrakeBoostPressure: nonqueued-receiver-com-spec{data-element=Value, init-value=constant-reference=CONST_VeSCMR_p_Lv2BrakeBoostPressure_Init}, required-interface=VeSCMR_p_Lv2BrakeBoostPressure
      VeSCMR_Pct_Lv2BrkTravelSts: nonqueued-receiver-com-spec{data-element=Value, init-value=constant-reference=CONST_VeSCMR_Pct_Lv2BrkTravelSts_Init}, required-interface=VeSCMR_Pct_Lv2BrkTravelSts
      VeSCMR_phi_Lv2LwsAngle: nonqueued-receiver-com-spec{data-element=Value, init-value=constant-reference=CONST_VeSCMR_phi_Lv2LwsAngle_Init}, required-interface=VeSCMR_phi_Lv2LwsAngle
      VeSCMR_r_Lv2TransTrqRatio: nonqueued-receiver-com-spec{data-element=Value, init-value=constant-reference=CONST_VeSCMR_r_Lv2TransTrqRatio_Init}, required-interface=VeSCMR_r_Lv2TransTrqRatio
      VeSCMR_T_Lv2RrTemp_Avl: nonqueued-receiver-com-spec{data-element=Value, init-value=constant-reference=CONST_VeSCMR_T_Lv2RrTemp_Avl_Init}, required-interface=VeSCMR_T_Lv2RrTemp_Avl
      VeSCMR_y_Lv2GearShiftType: nonqueued-receiver-com-spec{data-element=Value, init-value=constant-reference=CONST_VeSCMR_y_Lv2GearShiftType_Init}, required-interface=VeSCMR_y_Lv2GearShiftType
      VeSCMR_y_Lv2MRGB_Current_Gr: nonqueued-receiver-com-spec{data-element=Value, init-value=constant-reference=CONST_VeSCMR_y_Lv2MRGB_Current_Gr_Init}, required-interface=VeSCMR_y_Lv2MRGB_Current_Gr
      VeSCMR_y_Lv2MRGB_Target_Gr: nonqueued-receiver-com-spec{data-element=Value, init-value=constant-reference=CONST_VeSCMR_y_Lv2MRGB_Target_Gr_Init}, required-interface=VeSCMR_y_Lv2MRGB_Target_Gr
      VeSCMR_y_Lv2OperationalModeSts: nonqueued-receiver-com-spec{data-element=Value, init-value=constant-reference=CONST_VeSCMR_y_Lv2OperationalModeSts_Init}, required-interface=VeSCMR_y_Lv2OperationalModeSts
      VeGRAR_e_MSSBEV_eAWD_TargetSts: nonqueued-receiver-com-spec{data-element=Value, init-value=CeGRAR_e_TargetSts_Disable}, required-interface=VeGRAR_e_MSSBEV_eAWD_TargetSts
      VeGRAR_e_MSSBEV_eLSD_TargetSts: nonqueued-receiver-com-spec{data-element=Value, init-value=CeGRAR_e_TargetSts_Disable}, required-interface=VeGRAR_e_MSSBEV_eLSD_TargetSts
      VeGRAR_e_MSSBEV_WED_TargetSts: nonqueued-receiver-com-spec{data-element=Value, init-value=CeGRAR_e_TargetSts_Disable}, required-interface=VeGRAR_e_MSSBEV_WED_TargetSts
      VeTMDR_e_TrrnMd: nonqueued-receiver-com-spec{data-element=Value, init-value=CeTMDR_e_NotDefine}, required-interface=VeTMDR_e_TrrnMd
      VeTRGR_e_CurrentGear: nonqueued-receiver-com-spec{data-element=Value, init-value=constant-reference=CONST_VeTRGR_e_CurrentGear_Init}, required-interface=VeTRGR_e_CurrentGear
      VeVDDR_M_ToMaxFrntAtRipAWD_MtrCmnd: nonqueued-receiver-com-spec{data-element=Value, init-value=constant-reference=CONST_VeVDDR_M_ToMaxFrntAtRipAWD_MtrCmnd_Init}, required-interface=VeVDDR_M_ToMaxFrntAtRipAWD_MtrCmnd
      VeVDDR_M_ToMaxRrAtRipAWD_MtrCmnd: nonqueued-receiver-com-spec{data-element=Value, init-value=constant-reference=CONST_VeVDDR_M_ToMaxRrAtRipAWD_MtrCmnd_Init}, required-interface=VeVDDR_M_ToMaxRrAtRipAWD_MtrCmnd
      VeVDDR_M_ToMinFrntAtRipRgn_MtrCmnd: nonqueued-receiver-com-spec{data-element=Value, init-value=constant-reference=CONST_VeVDDR_M_ToMinFrntAtRipRgn_MtrCmnd_Init}, required-interface=VeVDDR_M_ToMinFrntAtRipRgn_MtrCmnd
      VeVDDR_M_ToMinRrAtRipRgn_MtrCmnd: nonqueued-receiver-com-spec{data-element=Value, init-value=constant-reference=CONST_VeVDDR_M_ToMinRrAtRipRgn_MtrCmnd_Init}, required-interface=VeVDDR_M_ToMinRrAtRipRgn_MtrCmnd
      VeVTVR_M_OptToFront: nonqueued-receiver-com-spec{data-element=Value, init-value=constant-reference=CONST_VeVTVR_M_OptToFront_Init}, required-interface=VeVTVR_M_OptToFront
      VeVTVR_M_OptToRear: nonqueued-receiver-com-spec{data-element=Value, init-value=constant-reference=CONST_VeVTVR_M_OptToRear_Init}, required-interface=VeVTVR_M_OptToRear
      VeVTVR_M_ToFrntMax_unintend: nonqueued-receiver-com-spec{data-element=Value, init-value=constant-reference=CONST_VeVTVR_M_ToFrntMax_unintend_Init}, required-interface=VeVTVR_M_ToFrntMax_unintend
      VeVTVR_M_ToFrntMin_unintend: nonqueued-receiver-com-spec{data-element=Value, init-value=constant-reference=CONST_VeVTVR_M_ToFrntMin_unintend_Init}, required-interface=VeVTVR_M_ToFrntMin_unintend
      VeVTVR_M_ToRrMax_unintend: nonqueued-receiver-com-spec{data-element=Value, init-value=constant-reference=CONST_VeVTVR_M_ToRrMax_unintend_Init}, required-interface=VeVTVR_M_ToRrMax_unintend
      VeVTVR_M_ToRrMin_unintend: nonqueued-receiver-com-spec{data-element=Value, init-value=constant-reference=CONST_VeVTVR_M_ToRrMin_unintend_Init}, required-interface=VeVTVR_M_ToRrMin_unintend
      VDAB_SL2outBEV_call: client-com-spec=VDAB_SL2outBEV_call, required-interface=cs_VDAB_SL2outBEV_call
      VDAB_SL2outBEV_run10ms_EndCheckpoint: client-com-spec=CheckpointReached, required-interface=WdgM_LocalSupervision
      VDAB_SL2outBEV_run10ms_StartCheckpoint: client-com-spec=CheckpointReached, required-interface=WdgM_LocalSupervision
    29 x provide port:
      VeSABR_b_SL2outBEV_VDAB_bTCS_SafActive: nonqueued-sender-com-spec{data-element=Value, init-value=constant-reference=CONST_VeSABR_b_SL2outBEV_VDAB_bTCS_SafActive_Init}, provided-interface=VeSABR_b_SL2outBEV_VDAB_bTCS_SafActive
      VeSABR_b_SL2outBEV_VDAB_bTV_SafActive: nonqueued-sender-com-spec{data-element=Value, init-value=constant-reference=CONST_VeSABR_b_SL2outBEV_VDAB_bTV_SafActive_Init}, provided-interface=VeSABR_b_SL2outBEV_VDAB_bTV_SafActive
      VeSABR_b_SL2outBEV_VDAB_eAWD_SafActive: nonqueued-sender-com-spec{data-element=Value, init-value=constant-reference=CONST_SL2outBEV_VDAB_eAWD_SafActive_Init}, provided-interface=VeSABR_b_SL2outBEV_VDAB_eAWD_SafActive
      VeSABR_b_SL2outBEV_VDAB_eDTC_SafActive: nonqueued-sender-com-spec{data-element=Value, init-value=constant-reference=CONST_VeSABR_b_SL2outBEV_VDAB_eDTC_SafActive_Init}, provided-interface=VeSABR_b_SL2outBEV_VDAB_eDTC_SafActive
      VeSABR_b_SL2outBEV_VDAB_eLSD_SafActive: nonqueued-sender-com-spec{data-element=Value, init-value=constant-reference=CONST_SL2outBEV_VDAB_eLSD_SafActive_Init}, provided-interface=VeSABR_b_SL2outBEV_VDAB_eLSD_SafActive
      VeSABR_b_SL2outBEV_VDAB_eTCS_SafActive: nonqueued-sender-com-spec{data-element=Value, init-value=constant-reference=CONST_VeSABR_b_SL2outBEV_VDAB_eTCS_SafActive_Init}, provided-interface=VeSABR_b_SL2outBEV_VDAB_eTCS_SafActive
      VeSABR_b_SL2outBEV_VDAB_Poff_SafActive: nonqueued-sender-com-spec{data-element=Value, init-value=constant-reference=CONST_VeSABR_b_SL2outBEV_VDAB_Poff_SafActive_Init}, provided-interface=VeSABR_b_SL2outBEV_VDAB_Poff_SafActive
      VeSABR_b_SL2outBEV_VDAB_Regen_SafActive: nonqueued-sender-com-spec{data-element=Value, init-value=constant-reference=CONST_VeSABR_b_SL2outBEV_VDAB_Regen_SafActive_Init}, provided-interface=VeSABR_b_SL2outBEV_VDAB_Regen_SafActive
      VeSABR_b_SL2outBEV_VDAB_WED_SafActive: nonqueued-sender-com-spec{data-element=Value, init-value=constant-reference=CONST_SL2outBEV_VDAB_WED_SafActive_Init}, provided-interface=VeSABR_b_SL2outBEV_VDAB_WED_SafActive
      VeSABR_e_FaultSts_AWD_SysPerf: nonqueued-sender-com-spec{data-element=Value, init-value=CeDFIB_e_Init}, provided-interface=VeSABR_e_FaultSts_AWD_SysPerf
      VeSABR_M_BrakeTCS_FrontTrqTarget: nonqueued-sender-com-spec{data-element=Value, init-value=constant-reference=CONST_VeSABR_M_BrakeTCS_FrontTrqTarget_Init}, provided-interface=VeSABR_M_BrakeTCS_FrontTrqTarget
      VeSABR_M_BrakeTCS_RearTrqTarget: nonqueued-sender-com-spec{data-element=Value, init-value=constant-reference=CONST_VeSABR_M_BrakeTCS_RearTrqTarget_Init}, provided-interface=VeSABR_M_BrakeTCS_RearTrqTarget
      VeSABR_M_BrakeTV_FrontTrqTarget: nonqueued-sender-com-spec{data-element=Value, init-value=constant-reference=CONST_VeSABR_M_BrakeTV_FrontTrqTarget_Init}, provided-interface=VeSABR_M_BrakeTV_FrontTrqTarget
      VeSABR_M_BrakeTV_RearTrqTarget: nonqueued-sender-com-spec{data-element=Value, init-value=constant-reference=CONST_VeSABR_M_BrakeTV_RearTrqTarget_Init}, provided-interface=VeSABR_M_BrakeTV_RearTrqTarget
      VeSABR_M_PoffComp_Target: nonqueued-sender-com-spec{data-element=Value, init-value=constant-reference=CONST_VeSABR_M_PoffComp_Target_Init}, provided-interface=VeSABR_M_PoffComp_Target
      VeSABR_M_RELSD_TgtTrq: nonqueued-sender-com-spec{data-element=Value, init-value=constant-reference=CONST_VeSABR_M_RELSD_TgtTrq_Init}, provided-interface=VeSABR_M_RELSD_TgtTrq
      VeSABR_y_BrakeTCS_FailureSts: nonqueued-sender-com-spec{data-element=Value, init-value=constant-reference=CONST_VeSABR_y_BrakeTCS_FailureSts_Init}, provided-interface=VeSABR_y_BrakeTCS_FailureSts
      VeSABR_y_BrakeTCS_FrontIntervReq: nonqueued-sender-com-spec{data-element=Value, init-value=constant-reference=CONST_VeSABR_y_BrakeTCS_FrontIntervReq_Init}, provided-interface=VeSABR_y_BrakeTCS_FrontIntervReq
      VeSABR_y_BrakeTCS_RearIntervReq: nonqueued-sender-com-spec{data-element=Value, init-value=constant-reference=CONST_VeSABR_y_BrakeTCS_RearIntervReq_Init}, provided-interface=VeSABR_y_BrakeTCS_RearIntervReq
      VeSABR_y_BrakeTCS_Sts: nonqueued-sender-com-spec{data-element=Value, init-value=constant-reference=CONST_VeSABR_y_BrakeTCS_Sts_Init}, provided-interface=VeSABR_y_BrakeTCS_Sts
      VeSABR_y_BrakeTV_FailureSts: nonqueued-sender-com-spec{data-element=Value, init-value=constant-reference=CONST_VeSABR_y_BrakeTV_FailureSts_Init}, provided-interface=VeSABR_y_BrakeTV_FailureSts
      VeSABR_y_BrakeTV_FrontIntervReq: nonqueued-sender-com-spec{data-element=Value, init-value=constant-reference=CONST_VeSABR_y_BrakeTV_FrontIntervReq_Init}, provided-interface=VeSABR_y_BrakeTV_FrontIntervReq
      VeSABR_y_BrakeTV_RearIntervReq: nonqueued-sender-com-spec{data-element=Value, init-value=constant-reference=CONST_VeSABR_y_BrakeTV_RearIntervReq_Init}, provided-interface=VeSABR_y_BrakeTV_RearIntervReq
      VeSABR_y_BrakeTV_Sts: nonqueued-sender-com-spec{data-element=Value, init-value=constant-reference=CONST_VeSABR_y_BrakeTV_Sts_Init}, provided-interface=VeSABR_y_BrakeTV_Sts
      VeSABR_y_PoffComp_FailureSts: nonqueued-sender-com-spec{data-element=Value, init-value=constant-reference=CONST_VeSABR_y_PoffComp_FailureSts_Init}, provided-interface=VeSABR_y_PoffComp_FailureSts
      VeSABR_y_PoffComp_Sts: nonqueued-sender-com-spec{data-element=Value, init-value=constant-reference=CONST_VeSABR_y_PoffComp_Sts_Init}, provided-interface=VeSABR_y_PoffComp_Sts
      VeSABR_y_RELSD_FailureSts: nonqueued-sender-com-spec{data-element=Value, init-value=constant-reference=CONST_VeSABR_y_RELSD_FailureSts_Init}, provided-interface=VeSABR_y_RELSD_FailureSts
      VeSABR_y_RELSD_Status: nonqueued-sender-com-spec{data-element=Value, init-value=constant-reference=CONST_VeSABR_y_RELSD_Status_Init}, provided-interface=VeSABR_y_RELSD_Status
      VDAB_SL2outBEV_event: server-com-spec{operation=VDAB_SL2outBEV_call, queue-length=1}, provided-interface=cs_VDAB_SL2outBEV_call
    behavior IB_SABR: constant-value-mapping=SABR_ConstantSpecificationMappingSet, data-type-mapping=msADTtoIDTMapping, handle-termination-and-restart=NO-SUPPORT
      timing event ev_10ms: start-on-event=VDAB_SL2outBEV_run10ms, period=0.01
      operation invoked event ev_run: start-on-event=VDAB_SL2outBEV_run, operation=VDAB_SL2outBEV_event.VDAB_SL2outBEV_call
      init event ev_pwrOn: start-on-event=VDAB_SL2outBEV_runPon
      included-data-type-sets:
        data-type=[t_BCA_BOOLEAN, t_BCA_RECMachineSts, tBasic_GasPedalPos2_prc, tBasic_InvrTransmRat, tBasic_SafLev2_HVMGM_Sts, tBasic_TotalTorque_Nm, t_InterlockSts]
        data-type=[t_BrakeBoostPressure, t_BrakePdlPosn, t_BrkPdl_Stat, t_BrkTrq, t_BrkTrq_Driver, t_LatAcceleration, t_LHF_Spin, t_LHFWheelSpeed, t_LHR_Spin, t_LHRWheelSpeed, t_LongAcceleration, t_LwsAngle, t_RHF_Spin, t_RHFWheelSpeed, t_RHR_Spin, t_RHRWheelSpeed, t_YawRate, t_MCPA_MaxTorq, t_MCPA_MinTorq, t_MCPB_MaxTorq, t_MCPB_MinTorq, t_ABSActive, t_COM_Sts, t_COM_RecSts, t_ABSFailSts, t_ABSHighSlip_Flag, t_ACC_Systemsts, t_ACC_Wheel_Torque, t_ACC_Wheel_Torque_Enabled, t_BMS_CntctrsMidTrmOpeningWarn, t_BMS_CntctrsShtTrmOpeningWarn, t_BMS_HV_BatActualPower, t_BMS_HV_Char_Main_Contac_Sts, t_BMS_HV_Current, t_BMS_HV_TractionBusVoltage, t_BrkPdl_Flt, t_Brk_Stat, t_CmdIgnSts, t_E1DriverDoorSts, t_EBDActive, t_EBDFailSts, t_EPBSts, t_ESCActive, t_ESCFailSts, t_ESC_OFF_Hrd_Sft_Button_sts, t_Edrv_stTq_MCPA_F, t_Edrv_stTq_MCPA, t_Edrv_stTq_MCPB_F, t_Edrv_stTq_MCPB, t_ElectricSteeringFailSts, t_FAD_Left_Status, t_FAD_Right_Status, t_Function2Sts, t_GearEngaged_VDCM, t_VDCM_PWT2_GasPedalPosition_VDCM, t_HillHolderFailSts, t_VDCM_PWT2_TerrainModeStat_VDCM, t_LHF_WheelSensorFailSts, t_LHR_WheelSensorFailSts, t_LatAccelerationFailSts, t_LongAccelerationFailSts, t_MCPA_6SO_Status, t_MCPA_CpbltySpdDivVolt, t_MCPA_DeratingFactor, t_MCPA_MtrIndex, t_MCPA_MtrMaxCpbltyTrq, t_MCPA_MtrMinCpbltyTrq, t_MCPA_RPM_V, t_MCPA_RPM, t_MCPA_TorqAchieved_AEMD_V, t_MCPA_TorqAchieved_AEMD, t_MCPA_Torque_Achieved_V, t_MCPA_Torque_Achieved, t_MCPB_6SO_Status, t_MCPB_CpbltySpdDivVolt, t_MCPB_DeratingFactor, t_MCPB_MtrIndex, t_MCPB_MtrMaxCpbltyTrq, t_MCPB_MtrMinCpbltyTrq, t_MCPB_RPM_V, t_MCPB_TorqAchieved_AEMD_V, t_MCPB_TorqAchieved_AEMD, t_MCPB_Torque_Achieved_V, t_MCPB_Torque_Achieved, t_MSSBEV_TgtSts, t_OperationalModeSts, t_Override_VDCM, t_PowertrainPrplsnActv_VDCM, t_RHF_WheelSensorFailSts, t_RHR_WheelSensorFailSts, t_RPM_MCPB, t_RegBrk_FailSts, t_RegenBrkFrontOffsetRequest, t_RegenBrkRearOffsetRequest, t_RollsModeAct, t_SBR1RowDriverSeatSts, t_SL2outBEV_VDAB_LnchCtrl_Sts, t_SL2outBEV_VDAB_VDCM_BrakeTCS_FailureSts, t_SL2outBEV_VDAB_VDCM_BrakeTCS_FrontIntervReq, t_SL2outBEV_VDAB_VDCM_BrakeTCS_FrontTrqTarget, t_SL2outBEV_VDAB_VDCM_BrakeTCS_RearIntervReq, t_SL2outBEV_VDAB_VDCM_BrakeTCS_RearTrqTarget, t_SL2outBEV_VDAB_VDCM_BrakeTCS_Sts, t_SL2outBEV_VDAB_VDCM_BrakeTV_FailureSts, t_SL2outBEV_VDAB_VDCM_BrakeTV_FrontIntervReq, t_SL2outBEV_VDAB_VDCM_BrakeTV_FrontTrqTarget, t_SL2outBEV_VDAB_VDCM_BrakeTV_RearIntervReq, t_SL2outBEV_VDAB_VDCM_BrakeTV_RearTrqTarget, t_SL2outBEV_VDAB_VDCM_BrakeTV_Sts, t_SL2outBEV_VDAB_VDCM_PoffComp_FailureSts, t_SL2outBEV_VDAB_VDCM_PoffComp_Sts, t_SL2outBEV_VDAB_VDCM_PoffComp_Target, t_Slip_Control_Sel, t_TorqueReduct, t_TorqueRequest, t_Torque_Vectoring_Sel, tBasic_AngleSpeed_radps, tBasic_AngleSpeed_degps, tBasic_State, tBasic_RecSt, tBasic_FaultConf, tBasic_FaultPunct, tBasic_Acc_mps2, tBasic_Acc_G, t_BCA_S16_mG_0, t_YawRateFailSts, t_eHLC_LnchCtrl_Sts, t_eHLC_VDCM_BrakeTCS_FrontIntervReq, t_eHLC_VDCM_BrakeTCS_FrontTrqTarget, t_eHLC_VDCM_BrakeTCS_RearIntervReq, t_eHLC_VDCM_BrakeTCS_RearTrqTarget, t_eHLC_VDCM_BrakeTV_FrontIntervReq, t_eHLC_VDCM_BrakeTV_FrontTrqTarget, t_eHLC_VDCM_BrakeTV_RearIntervReq, t_eHLC_VDCM_BrakeTV_RearTrqTarget, t_eHLC_VDCM_PoffComp_Target]
      runnable VDAB_SL2outBEV_run: can-be-invoked-concurrently=true
        data-receive-point-by-arguments:
          215 x access:
            DRP_VeADAR_e_LeftActuationStatus_Value: accessed-variable=VeADAR_e_LeftActuationStatus.Value
            DRP_VeADAR_e_RightActuationStatus_Value: accessed-variable=VeADAR_e_RightActuationStatus.Value
            DRP_VeATRR_M_ToReqPrdctd_Tact_Value: accessed-variable=VeATRR_M_ToReqPrdctd_Tact.Value
            DRP_VeGRAR_e_MSSBEV_Poff_TargetSts_Value: accessed-variable=VeGRAR_e_MSSBEV_Poff_TargetSts.Value
            DRP_VeGRAR_e_MSSBEV_Regen_TargetSts_Value: accessed-variable=VeGRAR_e_MSSBEV_Regen_TargetSts.Value
            DRP_VeGRAR_e_MSSBEV_WED_TargetSts_Value: accessed-variable=VeGRAR_e_MSSBEV_WED_TargetSts.Value
            DRP_VeGRAR_e_MSSBEV_bTCS_TargetSts_Value: accessed-variable=VeGRAR_e_MSSBEV_bTCS_TargetSts.Value
            DRP_VeGRAR_e_MSSBEV_bTV_TargetSts_Value: accessed-variable=VeGRAR_e_MSSBEV_bTV_TargetSts.Value
            DRP_VeGRAR_e_MSSBEV_eAWD_TargetSts_Value: accessed-variable=VeGRAR_e_MSSBEV_eAWD_TargetSts.Value
            DRP_VeGRAR_e_MSSBEV_eDTC_TargetSts_Value: accessed-variable=VeGRAR_e_MSSBEV_eDTC_TargetSts.Value
            DRP_VeGRAR_e_MSSBEV_eLSD_TargetSts_Value: accessed-variable=VeGRAR_e_MSSBEV_eLSD_TargetSts.Value
            DRP_VeGRAR_e_MSSBEV_eTCS_TargetSts_Value: accessed-variable=VeGRAR_e_MSSBEV_eTCS_TargetSts.Value
            DRP_VeHPMR_b_PropSysActv_Value: accessed-variable=VeHPMR_b_PropSysActv.Value
            DRP_VeHTDR_M_MtrA_TorqCmnd_Value: accessed-variable=VeHTDR_M_MtrA_TorqCmnd.Value
            DRP_VeHTDR_M_MtrB_TorqCmnd_Value: accessed-variable=VeHTDR_M_MtrB_TorqCmnd.Value
            DRP_VeHTDR_M_OutTorqReqNetRaw_Value: accessed-variable=VeHTDR_M_OutTorqReqNetRaw.Value
            DRP_VeHTDR_M_ToFMax_Ap_Value: accessed-variable=VeHTDR_M_ToFMax_Ap.Value
            DRP_VeHTDR_M_ToFMin_Am_Value: accessed-variable=VeHTDR_M_ToFMin_Am.Value
            DRP_VeHTDR_M_ToFTgt_AWD_Value: accessed-variable=VeHTDR_M_ToFTgt_AWD.Value
            DRP_VeHTDR_M_ToFTgt_postRegen_Value: accessed-variable=VeHTDR_M_ToFTgt_postRegen.Value
            DRP_VeHTDR_M_ToMaxFrntEff_Value: accessed-variable=VeHTDR_M_ToMaxFrntEff.Value
            DRP_VeHTDR_M_ToMaxRearEff_Value: accessed-variable=VeHTDR_M_ToMaxRearEff.Value
            DRP_VeHTDR_M_ToMinFrntEff_Value: accessed-variable=VeHTDR_M_ToMinFrntEff.Value
            DRP_VeHTDR_M_ToMinRearEff_Value: accessed-variable=VeHTDR_M_ToMinRearEff.Value
            DRP_VeHTDR_M_ToRMax_Bp_Value: accessed-variable=VeHTDR_M_ToRMax_Bp.Value
            DRP_VeHTDR_M_ToRMin_Bm_Value: accessed-variable=VeHTDR_M_ToRMin_Bm.Value
            DRP_VeHTDR_M_ToRTgt_AWD_Value: accessed-variable=VeHTDR_M_ToRTgt_AWD.Value
            DRP_VeHTDR_M_ToRTgt_postRegen_Value: accessed-variable=VeHTDR_M_ToRTgt_postRegen.Value
            DRP_VeINVR_e_MtrA_6SOEnbl_Value: accessed-variable=VeINVR_e_MtrA_6SOEnbl.Value
            DRP_VeINVR_e_MtrB_6SOEnbl_Value: accessed-variable=VeINVR_e_MtrB_6SOEnbl.Value
            DRP_VeLLDR_M_BrakeTCS_FrontTrqTarget_Value: accessed-variable=VeLLDR_M_BrakeTCS_FrontTrqTarget.Value
            DRP_VeLLDR_M_BrakeTCS_RearTrqTarget_Value: accessed-variable=VeLLDR_M_BrakeTCS_RearTrqTarget.Value
            DRP_VeLLDR_M_BrakeTV_FrontTrqTarget_Value: accessed-variable=VeLLDR_M_BrakeTV_FrontTrqTarget.Value
            DRP_VeLLDR_M_BrakeTV_RearTrqTarget_Value: accessed-variable=VeLLDR_M_BrakeTV_RearTrqTarget.Value
            DRP_VeLLDR_M_FrntAxlAdhMax_Value: accessed-variable=VeLLDR_M_FrntAxlAdhMax.Value
            DRP_VeLLDR_M_FrntAxlAdhMin_Value: accessed-variable=VeLLDR_M_FrntAxlAdhMin.Value
            DRP_VeLLDR_M_FrntAxlEffMax_Value: accessed-variable=VeLLDR_M_FrntAxlEffMax.Value
            DRP_VeLLDR_M_FrntAxlEffMin_Value: accessed-variable=VeLLDR_M_FrntAxlEffMin.Value
            DRP_VeLLDR_M_FrntAxlMax_CL_Value: accessed-variable=VeLLDR_M_FrntAxlMax_CL.Value
            DRP_VeLLDR_M_FrntAxlMax_OL_Value: accessed-variable=VeLLDR_M_FrntAxlMax_OL.Value
            DRP_VeLLDR_M_FrntAxlMin_CL_Value: accessed-variable=VeLLDR_M_FrntAxlMin_CL.Value
            DRP_VeLLDR_M_FrntAxlMin_OL_Value: accessed-variable=VeLLDR_M_FrntAxlMin_OL.Value
            DRP_VeLLDR_M_FrntAxlStrtgcMax_OL_Value: accessed-variable=VeLLDR_M_FrntAxlStrtgcMax_OL.Value
            DRP_VeLLDR_M_FrntAxlStrtgcMin_OL_Value: accessed-variable=VeLLDR_M_FrntAxlStrtgcMin_OL.Value
            DRP_VeLLDR_M_FrntAxlTactFastMax_OL_Value: accessed-variable=VeLLDR_M_FrntAxlTactFastMax_OL.Value
            DRP_VeLLDR_M_FrntAxlTactFastMin_OL_Value: accessed-variable=VeLLDR_M_FrntAxlTactFastMin_OL.Value
            DRP_VeLLDR_M_FrntAxlTactSlowMax_OL_Value: accessed-variable=VeLLDR_M_FrntAxlTactSlowMax_OL.Value
            DRP_VeLLDR_M_FrntAxlTactSlowMin_OL_Value: accessed-variable=VeLLDR_M_FrntAxlTactSlowMin_OL.Value
            DRP_VeLLDR_M_PoffComp_Target_Value: accessed-variable=VeLLDR_M_PoffComp_Target.Value
            DRP_VeLLDR_M_RrAxlAdhMax_Value: accessed-variable=VeLLDR_M_RrAxlAdhMax.Value
            DRP_VeLLDR_M_RrAxlAdhMin_Value: accessed-variable=VeLLDR_M_RrAxlAdhMin.Value
            DRP_VeLLDR_M_RrAxlEffMax_Value: accessed-variable=VeLLDR_M_RrAxlEffMax.Value
            DRP_VeLLDR_M_RrAxlEffMin_Value: accessed-variable=VeLLDR_M_RrAxlEffMin.Value
            DRP_VeLLDR_M_RrAxlMax_CL_Value: accessed-variable=VeLLDR_M_RrAxlMax_CL.Value
            DRP_VeLLDR_M_RrAxlMax_OL_Value: accessed-variable=VeLLDR_M_RrAxlMax_OL.Value
            DRP_VeLLDR_M_RrAxlMin_CL_Value: accessed-variable=VeLLDR_M_RrAxlMin_CL.Value
            DRP_VeLLDR_M_RrAxlMin_OL_Value: accessed-variable=VeLLDR_M_RrAxlMin_OL.Value
            DRP_VeLLDR_M_RrAxlStrtgcMax_OL_Value: accessed-variable=VeLLDR_M_RrAxlStrtgcMax_OL.Value
            DRP_VeLLDR_M_RrAxlStrtgcMin_OL_Value: accessed-variable=VeLLDR_M_RrAxlStrtgcMin_OL.Value
            DRP_VeLLDR_M_RrAxlTactFastMax_OL_Value: accessed-variable=VeLLDR_M_RrAxlTactFastMax_OL.Value
            DRP_VeLLDR_M_RrAxlTactFastMin_OL_Value: accessed-variable=VeLLDR_M_RrAxlTactFastMin_OL.Value
            DRP_VeLLDR_M_RrAxlTactSlowMax_OL_Value: accessed-variable=VeLLDR_M_RrAxlTactSlowMax_OL.Value
            DRP_VeLLDR_M_RrAxlTactSlowMin_OL_Value: accessed-variable=VeLLDR_M_RrAxlTactSlowMin_OL.Value
            DRP_VeLLDR_M_eHLC_eLSD_RELSD_TgtTrq_Value: accessed-variable=VeLLDR_M_eHLC_eLSD_RELSD_TgtTrq.Value
            DRP_VeLLDR_b_PerfAWDFlag_Value: accessed-variable=VeLLDR_b_PerfAWDFlag.Value
            DRP_VeLLDR_b_ZeroTrqAllwd_Value: accessed-variable=VeLLDR_b_ZeroTrqAllwd.Value
            DRP_VeLLDR_e_AWDDiscnctAllwd_Value: accessed-variable=VeLLDR_e_AWDDiscnctAllwd.Value
            DRP_VeLLDR_e_RrAxleLckrRelay_Value: accessed-variable=VeLLDR_e_RrAxleLckrRelay.Value
            DRP_VeLLDR_e_eHLC_Poff_QM_RecoveryStatus_Value: accessed-variable=VeLLDR_e_eHLC_Poff_QM_RecoveryStatus.Value
            DRP_VeLLDR_e_eHLC_WED_QM_RecoveryStatus_Value: accessed-variable=VeLLDR_e_eHLC_WED_QM_RecoveryStatus.Value
            DRP_VeLLDR_e_eHLC_bTCS_QM_RecoveryStatus_Value: accessed-variable=VeLLDR_e_eHLC_bTCS_QM_RecoveryStatus.Value
            DRP_VeLLDR_e_eHLC_bTV_QM_RecoveryStatus_Value: accessed-variable=VeLLDR_e_eHLC_bTV_QM_RecoveryStatus.Value
            DRP_VeLLDR_e_eHLC_eAWD_QM_RecoveryStatus_Value: accessed-variable=VeLLDR_e_eHLC_eAWD_QM_RecoveryStatus.Value
            DRP_VeLLDR_e_eHLC_eDTC_QM_RecoveryStatus_Value: accessed-variable=VeLLDR_e_eHLC_eDTC_QM_RecoveryStatus.Value
            DRP_VeLLDR_e_eHLC_eLOCK_QM_RecoveryStatus_Value: accessed-variable=VeLLDR_e_eHLC_eLOCK_QM_RecoveryStatus.Value
            DRP_VeLLDR_e_eHLC_eLSD_QM_RecoveryStatus_Value: accessed-variable=VeLLDR_e_eHLC_eLSD_QM_RecoveryStatus.Value
            DRP_VeLLDR_e_eHLC_eTCS_QM_RecoveryStatus_Value: accessed-variable=VeLLDR_e_eHLC_eTCS_QM_RecoveryStatus.Value
            DRP_VeLLDR_r_RipAWD_Value: accessed-variable=VeLLDR_r_RipAWD.Value
            DRP_VeLLDR_r_RipRegen_Value: accessed-variable=VeLLDR_r_RipRegen.Value
            DRP_VeLLDR_r_eTCS_TireTolQual_FL_Value: accessed-variable=VeLLDR_r_eTCS_TireTolQual_FL.Value
            DRP_VeLLDR_r_eTCS_TireTolQual_FR_Value: accessed-variable=VeLLDR_r_eTCS_TireTolQual_FR.Value
            DRP_VeLLDR_r_eTCS_TireTolQual_RL_Value: accessed-variable=VeLLDR_r_eTCS_TireTolQual_RL.Value
            DRP_VeLLDR_r_eTCS_TireTolQual_RR_Value: accessed-variable=VeLLDR_r_eTCS_TireTolQual_RR.Value
            DRP_VeLLDR_r_eTCS_TireTolRatio_FL_Value: accessed-variable=VeLLDR_r_eTCS_TireTolRatio_FL.Value
            DRP_VeLLDR_r_eTCS_TireTolRatio_FR_Value: accessed-variable=VeLLDR_r_eTCS_TireTolRatio_FR.Value
            DRP_VeLLDR_r_eTCS_TireTolRatio_RL_Value: accessed-variable=VeLLDR_r_eTCS_TireTolRatio_RL.Value
            DRP_VeLLDR_r_eTCS_TireTolRatio_RR_Value: accessed-variable=VeLLDR_r_eTCS_TireTolRatio_RR.Value
            DRP_VeLLDR_v_eTCS_VxEst_kmph_Value: accessed-variable=VeLLDR_v_eTCS_VxEst_kmph.Value
            DRP_VeLLDR_y_BrakeTCS_FrontIntervReq_Value: accessed-variable=VeLLDR_y_BrakeTCS_FrontIntervReq.Value
            DRP_VeLLDR_y_BrakeTCS_RearIntervReq_Value: accessed-variable=VeLLDR_y_BrakeTCS_RearIntervReq.Value
            DRP_VeLLDR_y_BrakeTV_FrontIntervReq_Value: accessed-variable=VeLLDR_y_BrakeTV_FrontIntervReq.Value
            DRP_VeLLDR_y_BrakeTV_RearIntervReq_Value: accessed-variable=VeLLDR_y_BrakeTV_RearIntervReq.Value
            DRP_VePSMR_Pct_Lv2AccelPdlPos_Value: accessed-variable=VePSMR_Pct_Lv2AccelPdlPos.Value
            DRP_VePSMR_b_Lv2AccelPdlPosFlt_Value: accessed-variable=VePSMR_b_Lv2AccelPdlPosFlt.Value
            DRP_VeRGNR_M_RegenBrkOutTorqCap_Frnt_Value: accessed-variable=VeRGNR_M_RegenBrkOutTorqCap_Frnt.Value
            DRP_VeRGNR_M_RegenBrkOutTorqCap_Rear_Value: accessed-variable=VeRGNR_M_RegenBrkOutTorqCap_Rear.Value
            DRP_VeRGNR_r_RIPEfficiency_Value: accessed-variable=VeRGNR_r_RIPEfficiency.Value
            DRP_VeSCMR_M_Lv2BrkTrq_Value: accessed-variable=VeSCMR_M_Lv2BrkTrq.Value
            DRP_VeSCMR_M_Lv2BrkTrqDriver_Value: accessed-variable=VeSCMR_M_Lv2BrkTrqDriver.Value
            DRP_VeSCMR_M_Lv2MtrA_MaxTrq_Value: accessed-variable=VeSCMR_M_Lv2MtrA_MaxTrq.Value
            DRP_VeSCMR_M_Lv2MtrA_MinTrq_Value: accessed-variable=VeSCMR_M_Lv2MtrA_MinTrq.Value
            DRP_VeSCMR_M_Lv2MtrA_TrqAchieved_Value: accessed-variable=VeSCMR_M_Lv2MtrA_TrqAchieved.Value
            DRP_VeSCMR_M_Lv2MtrA_TrqAchieved_NoAEMD_Value: accessed-variable=VeSCMR_M_Lv2MtrA_TrqAchieved_NoAEMD.Value
            DRP_VeSCMR_M_Lv2MtrB_MaxTrq_Value: accessed-variable=VeSCMR_M_Lv2MtrB_MaxTrq.Value
            DRP_VeSCMR_M_Lv2MtrB_MinTrq_Value: accessed-variable=VeSCMR_M_Lv2MtrB_MinTrq.Value
            DRP_VeSCMR_M_Lv2MtrB_TrqAchieved_Value: accessed-variable=VeSCMR_M_Lv2MtrB_TrqAchieved.Value
            DRP_VeSCMR_M_Lv2MtrB_TrqAchieved_NoAEMD_Value: accessed-variable=VeSCMR_M_Lv2MtrB_TrqAchieved_NoAEMD.Value
            DRP_VeSCMR_M_Lv2RrLkTrq_Value: accessed-variable=VeSCMR_M_Lv2RrLkTrq.Value
            DRP_VeSCMR_Pct_Lv2BrkTravelSts_Value: accessed-variable=VeSCMR_Pct_Lv2BrkTravelSts.Value
            DRP_VeSCMR_T_Lv2RrTemp_Avl_Value: accessed-variable=VeSCMR_T_Lv2RrTemp_Avl.Value
            DRP_VeSCMR_a_Lv2LatAcceleration_Value: accessed-variable=VeSCMR_a_Lv2LatAcceleration.Value
            DRP_VeSCMR_a_Lv2LongAcceleration_Value: accessed-variable=VeSCMR_a_Lv2LongAcceleration.Value
            DRP_VeSCMR_b_Lv2ABSActive_Value: accessed-variable=VeSCMR_b_Lv2ABSActive.Value
            DRP_VeSCMR_b_Lv2ABSActive_FA_Value: accessed-variable=VeSCMR_b_Lv2ABSActive_FA.Value
            DRP_VeSCMR_b_Lv2ABSFailSts_Value: accessed-variable=VeSCMR_b_Lv2ABSFailSts.Value
            DRP_VeSCMR_b_Lv2ABSFailSts_FA_Value: accessed-variable=VeSCMR_b_Lv2ABSFailSts_FA.Value
            DRP_VeSCMR_b_Lv2ACC_SystemSts_FA_Value: accessed-variable=VeSCMR_b_Lv2ACC_SystemSts_FA.Value
            DRP_VeSCMR_b_Lv2BrkBoostPressure_FA_Value: accessed-variable=VeSCMR_b_Lv2BrkBoostPressure_FA.Value
            DRP_VeSCMR_b_Lv2BrkPdlStat_FA_Value: accessed-variable=VeSCMR_b_Lv2BrkPdlStat_FA.Value
            DRP_VeSCMR_b_Lv2BrkPdl_Flt_Value: accessed-variable=VeSCMR_b_Lv2BrkPdl_Flt.Value
            DRP_VeSCMR_b_Lv2BrkPdl_Flt_FA_Value: accessed-variable=VeSCMR_b_Lv2BrkPdl_Flt_FA.Value
            DRP_VeSCMR_b_Lv2BrkTravelSts_FA_Value: accessed-variable=VeSCMR_b_Lv2BrkTravelSts_FA.Value
            DRP_VeSCMR_b_Lv2BrkTrqDriver_FA_Value: accessed-variable=VeSCMR_b_Lv2BrkTrqDriver_FA.Value
            DRP_VeSCMR_b_Lv2BrkTrq_FA_Value: accessed-variable=VeSCMR_b_Lv2BrkTrq_FA.Value
            DRP_VeSCMR_b_Lv2Brk_Stat_FA_Value: accessed-variable=VeSCMR_b_Lv2Brk_Stat_FA.Value
            DRP_VeSCMR_b_Lv2EPB_HoldSts_FA_Value: accessed-variable=VeSCMR_b_Lv2EPB_HoldSts_FA.Value
            DRP_VeSCMR_b_Lv2ESC_Active_Value: accessed-variable=VeSCMR_b_Lv2ESC_Active.Value
            DRP_VeSCMR_b_Lv2ESC_Active_FA_Value: accessed-variable=VeSCMR_b_Lv2ESC_Active_FA.Value
            DRP_VeSCMR_b_Lv2ESC_FailSts_Value: accessed-variable=VeSCMR_b_Lv2ESC_FailSts.Value
            DRP_VeSCMR_b_Lv2ESC_FailSts_FA_Value: accessed-variable=VeSCMR_b_Lv2ESC_FailSts_FA.Value
            DRP_VeSCMR_b_Lv2Function2Sts_Value: accessed-variable=VeSCMR_b_Lv2Function2Sts.Value
            DRP_VeSCMR_b_Lv2Function2Sts_FA_Value: accessed-variable=VeSCMR_b_Lv2Function2Sts_FA.Value
            DRP_VeSCMR_b_Lv2GearShiftType_FA_Value: accessed-variable=VeSCMR_b_Lv2GearShiftType_FA.Value
            DRP_VeSCMR_b_Lv2KeySts_FA_Value: accessed-variable=VeSCMR_b_Lv2KeySts_FA.Value
            DRP_VeSCMR_b_Lv2LatAccelerationFailSts_Value: accessed-variable=VeSCMR_b_Lv2LatAccelerationFailSts.Value
            DRP_VeSCMR_b_Lv2LatAccelerationFailSts_FA_Value: accessed-variable=VeSCMR_b_Lv2LatAccelerationFailSts_FA.Value
            DRP_VeSCMR_b_Lv2LatAcceleration_FA_Value: accessed-variable=VeSCMR_b_Lv2LatAcceleration_FA.Value
            DRP_VeSCMR_b_Lv2LongAccelerationFailSts_Value: accessed-variable=VeSCMR_b_Lv2LongAccelerationFailSts.Value
            DRP_VeSCMR_b_Lv2LongAccelerationFailSts_FA_Value: accessed-variable=VeSCMR_b_Lv2LongAccelerationFailSts_FA.Value
            DRP_VeSCMR_b_Lv2LongAcceleration_FA_Value: accessed-variable=VeSCMR_b_Lv2LongAcceleration_FA.Value
            DRP_VeSCMR_b_Lv2LwsAngle_FA_Value: accessed-variable=VeSCMR_b_Lv2LwsAngle_FA.Value
            DRP_VeSCMR_b_Lv2MRGB_Current_Gr_FA_Value: accessed-variable=VeSCMR_b_Lv2MRGB_Current_Gr_FA.Value
            DRP_VeSCMR_b_Lv2MRGB_Target_Gr_FA_Value: accessed-variable=VeSCMR_b_Lv2MRGB_Target_Gr_FA.Value
            DRP_VeSCMR_b_Lv2MtrA_MaxTrq_FA_Value: accessed-variable=VeSCMR_b_Lv2MtrA_MaxTrq_FA.Value
            DRP_VeSCMR_b_Lv2MtrA_MinTrq_FA_Value: accessed-variable=VeSCMR_b_Lv2MtrA_MinTrq_FA.Value
            DRP_VeSCMR_b_Lv2MtrA_Spd_Vld_Value: accessed-variable=VeSCMR_b_Lv2MtrA_Spd_Vld.Value
            DRP_VeSCMR_b_Lv2MtrA_TrqAchieved_NoAEMD_FA_Value: accessed-variable=VeSCMR_b_Lv2MtrA_TrqAchieved_NoAEMD_FA.Value
            DRP_VeSCMR_b_Lv2MtrA_TrqAchieved_Vld_Value: accessed-variable=VeSCMR_b_Lv2MtrA_TrqAchieved_Vld.Value
            DRP_VeSCMR_b_Lv2MtrB_MaxTrq_FA_Value: accessed-variable=VeSCMR_b_Lv2MtrB_MaxTrq_FA.Value
            DRP_VeSCMR_b_Lv2MtrB_MinTrq_FA_Value: accessed-variable=VeSCMR_b_Lv2MtrB_MinTrq_FA.Value
            DRP_VeSCMR_b_Lv2MtrB_Spd_Vld_Value: accessed-variable=VeSCMR_b_Lv2MtrB_Spd_Vld.Value
            DRP_VeSCMR_b_Lv2MtrB_TrqAchieved_NoAEMD_FA_Value: accessed-variable=VeSCMR_b_Lv2MtrB_TrqAchieved_NoAEMD_FA.Value
            DRP_VeSCMR_b_Lv2MtrB_TrqAchieved_Vld_Value: accessed-variable=VeSCMR_b_Lv2MtrB_TrqAchieved_Vld.Value
            DRP_VeSCMR_b_Lv2OperationalModeSts_FA_Value: accessed-variable=VeSCMR_b_Lv2OperationalModeSts_FA.Value
            DRP_VeSCMR_b_Lv2RollsModeAct_Value: accessed-variable=VeSCMR_b_Lv2RollsModeAct.Value
            DRP_VeSCMR_b_Lv2RollsModeAct_FA_Value: accessed-variable=VeSCMR_b_Lv2RollsModeAct_FA.Value
            DRP_VeSCMR_b_Lv2RrLkTrq_FA_Value: accessed-variable=VeSCMR_b_Lv2RrLkTrq_FA.Value
            DRP_VeSCMR_b_Lv2RrSysStat_FA_Value: accessed-variable=VeSCMR_b_Lv2RrSysStat_FA.Value
            DRP_VeSCMR_b_Lv2RrTemp_Avl_FA_Value: accessed-variable=VeSCMR_b_Lv2RrTemp_Avl_FA.Value
            DRP_VeSCMR_b_Lv2TransTrqRatio_FA_Value: accessed-variable=VeSCMR_b_Lv2TransTrqRatio_FA.Value
            DRP_VeSCMR_b_Lv2WhlDirFL_Stat_FA_Value: accessed-variable=VeSCMR_b_Lv2WhlDirFL_Stat_FA.Value
            DRP_VeSCMR_b_Lv2WhlDirFR_Stat_FA_Value: accessed-variable=VeSCMR_b_Lv2WhlDirFR_Stat_FA.Value
            DRP_VeSCMR_b_Lv2WhlDirRL_Stat_FA_Value: accessed-variable=VeSCMR_b_Lv2WhlDirRL_Stat_FA.Value
            DRP_VeSCMR_b_Lv2WhlDirRR_Stat_FA_Value: accessed-variable=VeSCMR_b_Lv2WhlDirRR_Stat_FA.Value
            DRP_VeSCMR_b_Lv2WhlFL_Spd_FA_Value: accessed-variable=VeSCMR_b_Lv2WhlFL_Spd_FA.Value
            DRP_VeSCMR_b_Lv2WhlFR_Spd_FA_Value: accessed-variable=VeSCMR_b_Lv2WhlFR_Spd_FA.Value
            DRP_VeSCMR_b_Lv2WhlRL_Spd_FA_Value: accessed-variable=VeSCMR_b_Lv2WhlRL_Spd_FA.Value
            DRP_VeSCMR_b_Lv2WhlRR_Spd_FA_Value: accessed-variable=VeSCMR_b_Lv2WhlRR_Spd_FA.Value
            DRP_VeSCMR_b_Lv2WhlSensFailFL_Value: accessed-variable=VeSCMR_b_Lv2WhlSensFailFL.Value
            DRP_VeSCMR_b_Lv2WhlSensFailFL_FA_Value: accessed-variable=VeSCMR_b_Lv2WhlSensFailFL_FA.Value
            DRP_VeSCMR_b_Lv2WhlSensFailFR_Value: accessed-variable=VeSCMR_b_Lv2WhlSensFailFR.Value
            DRP_VeSCMR_b_Lv2WhlSensFailFR_FA_Value: accessed-variable=VeSCMR_b_Lv2WhlSensFailFR_FA.Value
            DRP_VeSCMR_b_Lv2WhlSensFailRL_Value: accessed-variable=VeSCMR_b_Lv2WhlSensFailRL.Value
            DRP_VeSCMR_b_Lv2WhlSensFailRL_FA_Value: accessed-variable=VeSCMR_b_Lv2WhlSensFailRL_FA.Value
            DRP_VeSCMR_b_Lv2WhlSensFailRR_Value: accessed-variable=VeSCMR_b_Lv2WhlSensFailRR.Value
            DRP_VeSCMR_b_Lv2WhlSensFailRR_FA_Value: accessed-variable=VeSCMR_b_Lv2WhlSensFailRR_FA.Value
            DRP_VeSCMR_b_Lv2YawRateFailSts_Value: accessed-variable=VeSCMR_b_Lv2YawRateFailSts.Value
            DRP_VeSCMR_b_Lv2YawRateFailSts_FA_Value: accessed-variable=VeSCMR_b_Lv2YawRateFailSts_FA.Value
            DRP_VeSCMR_b_Lv2YawRate_FA_Value: accessed-variable=VeSCMR_b_Lv2YawRate_FA.Value
            DRP_VeSCMR_dphi_Lv2YawRate_Value: accessed-variable=VeSCMR_dphi_Lv2YawRate.Value
            DRP_VeSCMR_e_Lv2ACC_SystemSts_Value: accessed-variable=VeSCMR_e_Lv2ACC_SystemSts.Value
            DRP_VeSCMR_e_Lv2BrkPdlStat_Value: accessed-variable=VeSCMR_e_Lv2BrkPdlStat.Value
            DRP_VeSCMR_e_Lv2Brk_Stat_Value: accessed-variable=VeSCMR_e_Lv2Brk_Stat.Value
            DRP_VeSCMR_e_Lv2EPB_HoldSts_Value: accessed-variable=VeSCMR_e_Lv2EPB_HoldSts.Value
            DRP_VeSCMR_e_Lv2KeySts_Value: accessed-variable=VeSCMR_e_Lv2KeySts.Value
            DRP_VeSCMR_e_Lv2RrSysStat_Value: accessed-variable=VeSCMR_e_Lv2RrSysStat.Value
            DRP_VeSCMR_e_Lv2WhlDirFL_Stat_Value: accessed-variable=VeSCMR_e_Lv2WhlDirFL_Stat.Value
            DRP_VeSCMR_e_Lv2WhlDirFR_Stat_Value: accessed-variable=VeSCMR_e_Lv2WhlDirFR_Stat.Value
            DRP_VeSCMR_e_Lv2WhlDirRL_Stat_Value: accessed-variable=VeSCMR_e_Lv2WhlDirRL_Stat.Value
            DRP_VeSCMR_e_Lv2WhlDirRR_Stat_Value: accessed-variable=VeSCMR_e_Lv2WhlDirRR_Stat.Value
            DRP_VeSCMR_n_Lv2MtrA_Spd_Value: accessed-variable=VeSCMR_n_Lv2MtrA_Spd.Value
            DRP_VeSCMR_n_Lv2MtrB_Spd_Value: accessed-variable=VeSCMR_n_Lv2MtrB_Spd.Value
            DRP_VeSCMR_n_Lv2WhlFL_Spd_Value: accessed-variable=VeSCMR_n_Lv2WhlFL_Spd.Value
            DRP_VeSCMR_n_Lv2WhlFR_Spd_Value: accessed-variable=VeSCMR_n_Lv2WhlFR_Spd.Value
            DRP_VeSCMR_n_Lv2WhlRL_Spd_Value: accessed-variable=VeSCMR_n_Lv2WhlRL_Spd.Value
            DRP_VeSCMR_n_Lv2WhlRR_Spd_Value: accessed-variable=VeSCMR_n_Lv2WhlRR_Spd.Value
            DRP_VeSCMR_p_Lv2BrakeBoostPressure_Value: accessed-variable=VeSCMR_p_Lv2BrakeBoostPressure.Value
            DRP_VeSCMR_phi_Lv2LwsAngle_Value: accessed-variable=VeSCMR_phi_Lv2LwsAngle.Value
            DRP_VeSCMR_r_Lv2TransTrqRatio_Value: accessed-variable=VeSCMR_r_Lv2TransTrqRatio.Value
            DRP_VeSCMR_y_Lv2GearShiftType_Value: accessed-variable=VeSCMR_y_Lv2GearShiftType.Value
            DRP_VeSCMR_y_Lv2MRGB_Current_Gr_Value: accessed-variable=VeSCMR_y_Lv2MRGB_Current_Gr.Value
            DRP_VeSCMR_y_Lv2MRGB_Target_Gr_Value: accessed-variable=VeSCMR_y_Lv2MRGB_Target_Gr.Value
            DRP_VeSCMR_y_Lv2OperationalModeSts_Value: accessed-variable=VeSCMR_y_Lv2OperationalModeSts.Value
            DRP_VeTMDR_e_TrrnMd_Value: accessed-variable=VeTMDR_e_TrrnMd.Value
            DRP_VeTRGR_e_CurrentGear_Value: accessed-variable=VeTRGR_e_CurrentGear.Value
            DRP_VeVDDR_M_ToMaxFrntAtRipAWD_MtrCmnd_Value: accessed-variable=VeVDDR_M_ToMaxFrntAtRipAWD_MtrCmnd.Value
            DRP_VeVDDR_M_ToMaxRrAtRipAWD_MtrCmnd_Value: accessed-variable=VeVDDR_M_ToMaxRrAtRipAWD_MtrCmnd.Value
            DRP_VeVDDR_M_ToMinFrntAtRipRgn_MtrCmnd_Value: accessed-variable=VeVDDR_M_ToMinFrntAtRipRgn_MtrCmnd.Value
            DRP_VeVDDR_M_ToMinRrAtRipRgn_MtrCmnd_Value: accessed-variable=VeVDDR_M_ToMinRrAtRipRgn_MtrCmnd.Value
            DRP_VeVTVR_M_OptToFront_Value: accessed-variable=VeVTVR_M_OptToFront.Value
            DRP_VeVTVR_M_OptToRear_Value: accessed-variable=VeVTVR_M_OptToRear.Value
            DRP_VeVTVR_M_ToFrntMax_unintend_Value: accessed-variable=VeVTVR_M_ToFrntMax_unintend.Value
            DRP_VeVTVR_M_ToFrntMin_unintend_Value: accessed-variable=VeVTVR_M_ToFrntMin_unintend.Value
            DRP_VeVTVR_M_ToRrMax_unintend_Value: accessed-variable=VeVTVR_M_ToRrMax_unintend.Value
            DRP_VeVTVR_M_ToRrMin_unintend_Value: accessed-variable=VeVTVR_M_ToRrMin_unintend.Value
        data-send-points:
          28 x access:
            DSP_VeSABR_M_BrakeTCS_FrontTrqTarget_Value: accessed-variable=VeSABR_M_BrakeTCS_FrontTrqTarget.Value
            DSP_VeSABR_M_BrakeTCS_RearTrqTarget_Value: accessed-variable=VeSABR_M_BrakeTCS_RearTrqTarget.Value
            DSP_VeSABR_M_BrakeTV_FrontTrqTarget_Value: accessed-variable=VeSABR_M_BrakeTV_FrontTrqTarget.Value
            DSP_VeSABR_M_BrakeTV_RearTrqTarget_Value: accessed-variable=VeSABR_M_BrakeTV_RearTrqTarget.Value
            DSP_VeSABR_M_PoffComp_Target_Value: accessed-variable=VeSABR_M_PoffComp_Target.Value
            DSP_VeSABR_M_RELSD_TgtTrq_Value: accessed-variable=VeSABR_M_RELSD_TgtTrq.Value
            DSP_VeSABR_b_SL2outBEV_VDAB_Poff_SafActive_Value: accessed-variable=VeSABR_b_SL2outBEV_VDAB_Poff_SafActive.Value
            DSP_VeSABR_b_SL2outBEV_VDAB_Regen_SafActive_Value: accessed-variable=VeSABR_b_SL2outBEV_VDAB_Regen_SafActive.Value
            DSP_VeSABR_b_SL2outBEV_VDAB_WED_SafActive_Value: accessed-variable=VeSABR_b_SL2outBEV_VDAB_WED_SafActive.Value
            DSP_VeSABR_b_SL2outBEV_VDAB_bTCS_SafActive_Value: accessed-variable=VeSABR_b_SL2outBEV_VDAB_bTCS_SafActive.Value
            DSP_VeSABR_b_SL2outBEV_VDAB_bTV_SafActive_Value: accessed-variable=VeSABR_b_SL2outBEV_VDAB_bTV_SafActive.Value
            DSP_VeSABR_b_SL2outBEV_VDAB_eAWD_SafActive_Value: accessed-variable=VeSABR_b_SL2outBEV_VDAB_eAWD_SafActive.Value
            DSP_VeSABR_b_SL2outBEV_VDAB_eDTC_SafActive_Value: accessed-variable=VeSABR_b_SL2outBEV_VDAB_eDTC_SafActive.Value
            DSP_VeSABR_b_SL2outBEV_VDAB_eLSD_SafActive_Value: accessed-variable=VeSABR_b_SL2outBEV_VDAB_eLSD_SafActive.Value
            DSP_VeSABR_b_SL2outBEV_VDAB_eTCS_SafActive_Value: accessed-variable=VeSABR_b_SL2outBEV_VDAB_eTCS_SafActive.Value
            DSP_VeSABR_e_FaultSts_AWD_SysPerf_Value: accessed-variable=VeSABR_e_FaultSts_AWD_SysPerf.Value
            DSP_VeSABR_y_BrakeTCS_FailureSts_Value: accessed-variable=VeSABR_y_BrakeTCS_FailureSts.Value
            DSP_VeSABR_y_BrakeTCS_FrontIntervReq_Value: accessed-variable=VeSABR_y_BrakeTCS_FrontIntervReq.Value
            DSP_VeSABR_y_BrakeTCS_RearIntervReq_Value: accessed-variable=VeSABR_y_BrakeTCS_RearIntervReq.Value
            DSP_VeSABR_y_BrakeTCS_Sts_Value: accessed-variable=VeSABR_y_BrakeTCS_Sts.Value
            DSP_VeSABR_y_BrakeTV_FailureSts_Value: accessed-variable=VeSABR_y_BrakeTV_FailureSts.Value
            DSP_VeSABR_y_BrakeTV_FrontIntervReq_Value: accessed-variable=VeSABR_y_BrakeTV_FrontIntervReq.Value
            DSP_VeSABR_y_BrakeTV_RearIntervReq_Value: accessed-variable=VeSABR_y_BrakeTV_RearIntervReq.Value
            DSP_VeSABR_y_BrakeTV_Sts_Value: accessed-variable=VeSABR_y_BrakeTV_Sts.Value
            DSP_VeSABR_y_PoffComp_FailureSts_Value: accessed-variable=VeSABR_y_PoffComp_FailureSts.Value
            DSP_VeSABR_y_PoffComp_Sts_Value: accessed-variable=VeSABR_y_PoffComp_Sts.Value
            DSP_VeSABR_y_RELSD_FailureSts_Value: accessed-variable=VeSABR_y_RELSD_FailureSts.Value
            DSP_VeSABR_y_RELSD_Status_Value: accessed-variable=VeSABR_y_RELSD_Status.Value
      runnable VDAB_SL2outBEV_run10ms
        sync call SSCP_VDAB_SL2outBEV_call_run10ms: operation=VDAB_SL2outBEV_call.VDAB_SL2outBEV_call, timeout=1
        sync call SSCP_VDAB_SL2outBEV_run10ms_EndCheckpoint_CheckpointReached: operation=VDAB_SL2outBEV_run10ms_EndCheckpoint.CheckpointReached, timeout=1
        sync call SSCP_VDAB_SL2outBEV_run10ms_StartCheckpoint_CheckpointReached: operation=VDAB_SL2outBEV_run10ms_StartCheckpoint.CheckpointReached, timeout=1
      runnable VDAB_SL2outBEV_runPon
        sync call SSCP_VDAB_SL2outBEV_call_runPon: operation=VDAB_SL2outBEV_call.VDAB_SL2outBEV_call, timeout=1
